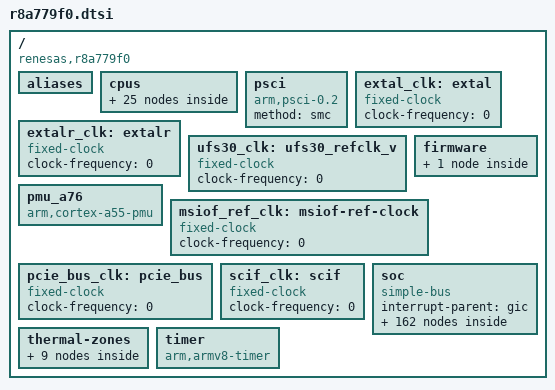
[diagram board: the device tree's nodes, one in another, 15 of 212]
// SPDX-License-Identifier: GPL-2.0
/*
 * Device Tree Source for the R-Car S4 (R8A779F0) SoC
 *
 * Copyright (C) 2021 Renesas Electronics Corp.
 */

#include <dt-bindings/clock/r8a779f0-cpg-mssr.h>
#include <dt-bindings/interrupt-controller/arm-gic.h>
#include <dt-bindings/power/r8a779f0-sysc.h>
#include <dt-bindings/ipmmu/rcar-ipmmu.h>
/ {
	compatible = "renesas,r8a779f0";
	#address-cells = <2>;
	#size-cells = <2>;

	aliases {
		i2c0 = &i2c0;
		i2c1 = &i2c1;
		i2c2 = &i2c2;
		i2c3 = &i2c3;
		i2c4 = &i2c4;
		i2c5 = &i2c5;
	};


	cpus {
		#address-cells = <1>;
		#size-cells = <0>;

		cpu-map {
			cluster0 {
				core0 {
					cpu = <&a55_0>;
				};
				core1 {
					cpu = <&a55_1>;
				};
			};
			cluster1 {
				core0 {
					cpu = <&a55_2>;
				};
				core1 {
					cpu = <&a55_3>;
				};
			};
			cluster2 {
				core0 {
					cpu = <&a55_4>;
				};
				core1 {
					cpu = <&a55_5>;
				};
			};
			cluster3 {
				core0 {
					cpu = <&a55_6>;
				};
				core1 {
					cpu = <&a55_7>;
				};
			};
		};

		a55_0: cpu@0 {
			compatible = "arm,cortex-a55";
			reg = <0>;
			device_type = "cpu";
			power-domains = <&sysc R8A779F0_PD_A1E0D0C0>;
			enable-method = "psci";
			next-level-cache = <&L3_CA55_0>;
		};

		a55_1: cpu@100 {
			compatible = "arm,cortex-a55";
			reg = <0x100>;
			device_type = "cpu";
			power-domains = <&sysc R8A779F0_PD_A1E0D0C1>;
			enable-method = "psci";
			next-level-cache = <&L3_CA55_0>;
		};

		a55_2: cpu@10000 {
			compatible = "arm,cortex-a55";
			reg = <0x10000>;
			device_type = "cpu";
			power-domains = <&sysc R8A779F0_PD_A1E0D1C0>;
			enable-method = "psci";
			next-level-cache = <&L3_CA55_1>;
		};

		a55_3: cpu@10100 {
			compatible = "arm,cortex-a55";
			reg = <0x10100>;
			device_type = "cpu";
			power-domains = <&sysc R8A779F0_PD_A1E0D1C1>;
			enable-method = "psci";
			next-level-cache = <&L3_CA55_1>;
		};

		a55_4: cpu@20000 {
			compatible = "arm,cortex-a55";
			reg = <0x20000>;
			device_type = "cpu";
			power-domains = <&sysc R8A779F0_PD_A1E1D0C0>;
			enable-method = "psci";
			next-level-cache = <&L3_CA55_2>;
		};

		a55_5: cpu@20100 {
			compatible = "arm,cortex-a55";
			reg = <0x20100>;
			device_type = "cpu";
			power-domains = <&sysc R8A779F0_PD_A1E1D0C1>;
			enable-method = "psci";
			next-level-cache = <&L3_CA55_2>;
		};

		a55_6: cpu@30000 {
			compatible = "arm,cortex-a55";
			reg = <0x30000>;
			device_type = "cpu";
			power-domains = <&sysc R8A779F0_PD_A1E1D1C0>;
			enable-method = "psci";
			next-level-cache = <&L3_CA55_3>;
		};

		a55_7: cpu@30100 {
			compatible = "arm,cortex-a55";
			reg = <0x30100>;
			device_type = "cpu";
			power-domains = <&sysc R8A779F0_PD_A1E1D1C1>;
			enable-method = "psci";
			next-level-cache = <&L3_CA55_3>;
		};

		L3_CA55_0: cache-controller-0 {
			compatible = "cache";
			power-domains = <&sysc R8A779F0_PD_A2E0D0>;
			cache-unified;
			cache-level = <3>;
		};

		L3_CA55_1: cache-controller-1 {
			compatible = "cache";
			power-domains = <&sysc R8A779F0_PD_A2E0D1>;
			cache-unified;
			cache-level = <3>;
		};

		L3_CA55_2: cache-controller-2 {
			compatible = "cache";
			power-domains = <&sysc R8A779F0_PD_A2E1D0>;
			cache-unified;
			cache-level = <3>;
		};

		L3_CA55_3: cache-controller-3 {
			compatible = "cache";
			power-domains = <&sysc R8A779F0_PD_A2E1D1>;
			cache-unified;
			cache-level = <3>;
		};
	};

	psci {
		compatible = "arm,psci-0.2";
		method = "smc";
	};

	extal_clk: extal {
		compatible = "fixed-clock";
		#clock-cells = <0>;
		/* This value must be overridden by the board */
		clock-frequency = <0>;
	};

	extalr_clk: extalr {
		compatible = "fixed-clock";
		#clock-cells = <0>;
		/* This value must be overridden by the board */
		clock-frequency = <0>;
	};

	ufs30_clk: ufs30_refclk_v {
		compatible = "fixed-clock";
		#clock-cells = <0>;
		/* This value must be overridden by the board */
		clock-frequency = <0>;
	};

	firmware {
		optee {
			compatible = "linaro,optee-tz";
			method = "smc";
		};
	};

	pmu_a76 {
		compatible = "arm,cortex-a55-pmu";
		interrupts-extended = <&gic GIC_PPI 7 IRQ_TYPE_LEVEL_LOW>;
	};

	/* MSIOF reference clock - to be overridden by boards that provide it */
	msiof_ref_clk: msiof-ref-clock {
		compatible = "fixed-clock";
		#clock-cells = <0>;
		clock-frequency = <0>;
	};

	/* External PCIe clock - can be overridden by the board */
	pcie_bus_clk: pcie_bus {
		compatible = "fixed-clock";
		#clock-cells = <0>;
		clock-frequency = <0>;
	};

	/* External SCIF clock - to be overridden by boards that provide it */
	scif_clk: scif {
		compatible = "fixed-clock";
		#clock-cells = <0>;
		clock-frequency = <0>;
	};

	soc: soc {
		compatible = "simple-bus";
		interrupt-parent = <&gic>;
		#address-cells = <2>;
		#size-cells = <2>;
		ranges;

		rwdt: watchdog@e6020000 {
			compatible = "renesas,r8a779f0-wdt",
				     "renesas,rcar-gen4-wdt";
			reg = <0 0xe6020000 0 0x0c>;
			clocks = <&cpg CPG_MOD 907>;
			power-domains = <&sysc R8A779F0_PD_ALWAYS_ON>;
			resets = <&cpg 907>;
			status = "disabled";
		};

		pfc: pin-controller@e6050000 {
			compatible = "renesas,pfc-r8a779f0";
			reg = <0 0xe6050000 0 0x16c>, <0 0xe6050800 0 0x16c>,
			      <0 0xe6051000 0 0x16c>, <0 0xe6051800 0 0x16c>,
			      <0 0xdfd90000 0 0x16c>, <0 0xdfd90800 0 0x16c>,
			      <0 0xdfd91000 0 0x16c>, <0 0xdfd91800 0 0x16c>;
		};

		gpio0: gpio@e6050180 {
			compatible = "renesas,gpio-r8a779f0";
			reg = <0 0xe6050180 0 0x54>;
			interrupts = <GIC_SPI 822 IRQ_TYPE_LEVEL_HIGH>;
			#gpio-cells = <2>;
			gpio-controller;
			gpio-ranges = <&pfc 0 0 21>;
			#interrupt-cells = <2>;
			interrupt-controller;
			clocks = <&cpg CPG_MOD 915>;
			power-domains = <&sysc R8A779F0_PD_ALWAYS_ON>;
			resets = <&cpg 915>;
		};

		gpio1: gpio@e6050980 {
			compatible = "renesas,gpio-r8a779f0";
			reg = <0 0xe6050980 0 0x54>;
			interrupts = <GIC_SPI 823 IRQ_TYPE_LEVEL_HIGH>;
			#gpio-cells = <2>;
			gpio-controller;
			gpio-ranges = <&pfc 0 32 25>;
			#interrupt-cells = <2>;
			interrupt-controller;
			clocks = <&cpg CPG_MOD 915>;
			power-domains = <&sysc R8A779F0_PD_ALWAYS_ON>;
			resets = <&cpg 915>;
		};

		gpio2: gpio@e6051180 {
			compatible = "renesas,gpio-r8a779f0";
			reg = <0 0xe6051180 0 0x54>;
			interrupts = <GIC_SPI 824 IRQ_TYPE_LEVEL_HIGH>;
			#gpio-cells = <2>;
			gpio-controller;
			gpio-ranges = <&pfc 0 64 17>;
			#interrupt-cells = <2>;
			interrupt-controller;
			clocks = <&cpg CPG_MOD 915>;
			power-domains = <&sysc R8A779F0_PD_ALWAYS_ON>;
			resets = <&cpg 915>;
		};

		gpio3: gpio@e6051980 {
			compatible = "renesas,gpio-r8a779f0";
			reg = <0 0xe6051980 0 0x54>;
			interrupts = <GIC_SPI 825 IRQ_TYPE_LEVEL_HIGH>;
			#gpio-cells = <2>;
			gpio-controller;
			gpio-ranges = <&pfc 0 96 19>;
			#interrupt-cells = <2>;
			interrupt-controller;
			clocks = <&cpg CPG_MOD 915>;
			power-domains = <&sysc R8A779F0_PD_ALWAYS_ON>;
			resets = <&cpg 915>;
		};

		gpio4: gpio@dfd90180 {
			compatible = "renesas,gpio-r8a779f0";
			reg = <0 0xdfd90180 0 0x54>;
			interrupts = <GIC_SPI 826 IRQ_TYPE_LEVEL_HIGH>;
			#gpio-cells = <2>;
			gpio-controller;
			gpio-ranges = <&pfc 0 128 31>;
			#interrupt-cells = <2>;
			interrupt-controller;
			clocks = <&cpg CPG_MOD 915>;
			power-domains = <&sysc R8A779F0_PD_ALWAYS_ON>;
			resets = <&cpg 915>;
		};

		cpg: clock-controller@e6150000 {
			compatible = "renesas,r8a779f0-cpg-mssr";
			reg = <0 0xe6150000 0 0x4000>;
			clocks = <&extal_clk>, <&extalr_clk>;
			clock-names = "extal", "extalr";
			#clock-cells = <2>;
			#power-domain-cells = <0>;
			#reset-cells = <1>;
		};

		rst: reset-controller@e6160000 {
			compatible = "renesas,r8a779f0-rst";
			reg = <0 0xe6160000 0 0x4000>;
		};

		sysc: system-controller@e6180000 {
			compatible = "renesas,r8a779f0-sysc";
			reg = <0 0xe6180000 0 0x4000>;
			#power-domain-cells = <1>;
		};

		i2c0: i2c@e6500000 {
			compatible = "renesas,i2c-r8a779f0",
				     "renesas,rcar-gen4-i2c";
			reg = <0 0xe6500000 0 0x40>;
			interrupts = <GIC_SPI 238 IRQ_TYPE_LEVEL_HIGH>;
			clocks = <&cpg CPG_MOD 518>;
			power-domains = <&sysc R8A779F0_PD_ALWAYS_ON>;
			resets = <&cpg 518>;
			/* dmas and dma-names placeholder */
			i2c-scl-internal-delay-ns = <110>;
			#address-cells = <1>;
			#size-cells = <0>;
			status = "disabled";
		};

		i2c1: i2c@e6508000 {
			compatible = "renesas,i2c-r8a779f0",
				     "renesas,rcar-gen4-i2c";
			reg = <0 0xe6508000 0 0x40>;
			interrupts = <GIC_SPI 239 IRQ_TYPE_LEVEL_HIGH>;
			clocks = <&cpg CPG_MOD 519>;
			power-domains = <&sysc R8A779F0_PD_ALWAYS_ON>;
			resets = <&cpg 519>;
			/* dmas and dma-names placeholder */
			i2c-scl-internal-delay-ns = <110>;
			#address-cells = <1>;
			#size-cells = <0>;
			status = "disabled";
		};

		i2c2: i2c@e6510000 {
			compatible = "renesas,i2c-r8a779f0",
				     "renesas,rcar-gen4-i2c";
			reg = <GIC_SPI 0xe6510000 0 0x40>;
			interrupts = <0 240 IRQ_TYPE_LEVEL_HIGH>;
			clocks = <&cpg CPG_MOD 520>;
			power-domains = <&sysc R8A779F0_PD_ALWAYS_ON>;
			resets = <&cpg 520>;
			/* dmas and dma-names placeholder */
			i2c-scl-internal-delay-ns = <110>;
			#address-cells = <1>;
			#size-cells = <0>;
			status = "disabled";
		};

		i2c3: i2c@e66d0000 {
			compatible = "renesas,i2c-r8a779f0",
				     "renesas,rcar-gen4-i2c";
			reg = <0 0xe66d0000 0 0x40>;
			interrupts = <GIC_SPI 241 IRQ_TYPE_LEVEL_HIGH>;
			clocks = <&cpg CPG_MOD 521>;
			power-domains = <&sysc R8A779F0_PD_ALWAYS_ON>;
			resets = <&cpg 521>;
			/* dmas and dma-names placeholder */
			i2c-scl-internal-delay-ns = <110>;
			#address-cells = <1>;
			#size-cells = <0>;
			status = "disabled";
		};

		i2c4: i2c@e66d8000 {
			compatible = "renesas,i2c-r8a779f0",
				     "renesas,rcar-gen4-i2c";
			reg = <0 0xe66d8000 0 0x40>;
			interrupts = <GIC_SPI 242 IRQ_TYPE_LEVEL_HIGH>;
			clocks = <&cpg CPG_MOD 522>;
			power-domains = <&sysc R8A779F0_PD_ALWAYS_ON>;
			resets = <&cpg 522>;
			/* dmas and dma-names placeholder */
			i2c-scl-internal-delay-ns = <110>;
			#address-cells = <1>;
			#size-cells = <0>;
			status = "disabled";
		};

		i2c5: i2c@e66e0000 {
			compatible = "renesas,i2c-r8a779f0",
				     "renesas,rcar-gen4-i2c";
			reg = <0 0xe66e0000 0 0x40>;
			interrupts = <GIC_SPI 243 IRQ_TYPE_LEVEL_HIGH>;
			clocks = <&cpg CPG_MOD 523>;
			power-domains = <&sysc R8A779F0_PD_ALWAYS_ON>;
			resets = <&cpg 523>;
			/* dmas and dma-names placeholder */
			i2c-scl-internal-delay-ns = <110>;
			#address-cells = <1>;
			#size-cells = <0>;
			status = "disabled";
		};

		tsc: thermal@e6198000 {
			compatible = "renesas,r8a779f0-thermal";
			reg = <0 0xe6198000 0 0x100>,
			      <0 0xe61a0000 0 0x100>,
			      <0 0xe61a8000 0 0x100>,
			      <0 0xe61b0000 0 0x100>;
			clocks = <&cpg CPG_MOD 919>;
			power-domains = <&sysc R8A779F0_PD_ALWAYS_ON>;
			resets = <&cpg 919>;
			#thermal-sensor-cells = <1>;
		};

		hscif0: serial@e6540000 {
			compatible = "renesas,hscif-r8a779f0",
				     "renesas,rcar-gen4-hscif", "renesas,hscif";
			reg = <0 0xe6540000 0 0x60>;
			interrupts = <GIC_SPI 245 IRQ_TYPE_LEVEL_HIGH>;
			clocks = <&cpg CPG_MOD 514>,
				 <&cpg CPG_CORE R8A779F0_CLK_S0D3>,
				 <&scif_clk>;
			clock-names = "fck", "brg_int", "scif_clk";
			/* dmas and dma-names placeholder */
			power-domains = <&sysc R8A779F0_PD_ALWAYS_ON>;
			resets = <&cpg 514>;
			status = "disabled";
		};

		hscif1: serial@e6550000 {
			compatible = "renesas,hscif-r8a779f0",
				     "renesas,rcar-gen4-hscif", "renesas,hscif";
			reg = <0 0xe6550000 0 0x60>;
			interrupts = <GIC_SPI 246 IRQ_TYPE_LEVEL_HIGH>;
			clocks = <&cpg CPG_MOD 515>,
				 <&cpg CPG_CORE R8A779F0_CLK_S0D3>,
				 <&scif_clk>;
			clock-names = "fck", "brg_int", "scif_clk";
			/* dmas and dma-names placeholder */
			power-domains = <&sysc R8A779F0_PD_ALWAYS_ON>;
			resets = <&cpg 515>;
			status = "disabled";
		};

		hscif2: serial@e6560000 {
			compatible = "renesas,hscif-r8a779f0",
				     "renesas,rcar-gen4-hscif", "renesas,hscif";
			reg = <0 0xe6560000 0 0x60>;
			interrupts = <GIC_SPI 247 IRQ_TYPE_LEVEL_HIGH>;
			clocks = <&cpg CPG_MOD 516>,
				 <&cpg CPG_CORE R8A779F0_CLK_S0D3>,
				 <&scif_clk>;
			clock-names = "fck", "brg_int", "scif_clk";
			/* dmas and dma-names placeholder */
			power-domains = <&sysc R8A779F0_PD_ALWAYS_ON>;
			resets = <&cpg 516>;
			status = "disabled";
		};

		hscif3: serial@e66a0000 {
			compatible = "renesas,hscif-r8a779f0",
				     "renesas,rcar-gen4-hscif", "renesas,hscif";
			reg = <0 0xe66a0000 0 0x60>;
			interrupts = <GIC_SPI 248 IRQ_TYPE_LEVEL_HIGH>;
			clocks = <&cpg CPG_MOD 517>,
				 <&cpg CPG_CORE R8A779F0_CLK_S0D3>,
				 <&scif_clk>;
			clock-names = "fck", "brg_int", "scif_clk";
			/* dmas and dma-names placeholder */
			power-domains = <&sysc R8A779F0_PD_ALWAYS_ON>;
			resets = <&cpg 517>;
			status = "disabled";
		};

		rswitch: ethernet@e68c0000 {
			compatible = "renesas,etherswitch-r8a779f0",
				     "renesas,etherswitch";
			reg = <0 0xe68c0000 0 0x00020000>,
			      <0 0xe6444000 0 0x2800>;
			reg-names = "iobase", "serdes";
			interrupts = <GIC_SPI 280 IRQ_TYPE_LEVEL_HIGH>,
				     <GIC_SPI 281 IRQ_TYPE_LEVEL_HIGH>,
				     <GIC_SPI 282 IRQ_TYPE_LEVEL_HIGH>,
				     <GIC_SPI 283 IRQ_TYPE_LEVEL_HIGH>,
				     <GIC_SPI 284 IRQ_TYPE_LEVEL_HIGH>,
				     <GIC_SPI 285 IRQ_TYPE_LEVEL_HIGH>,
				     <GIC_SPI 286 IRQ_TYPE_LEVEL_HIGH>,
				     <GIC_SPI 287 IRQ_TYPE_LEVEL_HIGH>,
				     <GIC_SPI 288 IRQ_TYPE_LEVEL_HIGH>,
				     <GIC_SPI 289 IRQ_TYPE_LEVEL_HIGH>,
				     <GIC_SPI 290 IRQ_TYPE_LEVEL_HIGH>,
				     <GIC_SPI 291 IRQ_TYPE_LEVEL_HIGH>,
				     <GIC_SPI 292 IRQ_TYPE_LEVEL_HIGH>,
				     <GIC_SPI 293 IRQ_TYPE_LEVEL_HIGH>,
				     <GIC_SPI 294 IRQ_TYPE_LEVEL_HIGH>,
				     <GIC_SPI 295 IRQ_TYPE_LEVEL_HIGH>,
				     <GIC_SPI 296 IRQ_TYPE_LEVEL_HIGH>,
				     <GIC_SPI 297 IRQ_TYPE_LEVEL_HIGH>,
				     <GIC_SPI 298 IRQ_TYPE_LEVEL_HIGH>,
				     <GIC_SPI 299 IRQ_TYPE_LEVEL_HIGH>;
			interrupt-names = "gwca0_rxtx0", "gwca0_rxtx1",
					  "gwca0_rxtx2", "gwca0_rxtx3",
					  "gwca0_rxtx4", "gwca0_rxtx5",
					  "gwca0_rxtx6", "gwca0_rxtx7",
					  "gwca1_rxtx0", "gwca1_rxtx1",
					  "gwca1_rxtx2", "gwca1_rxtx3",
					  "gwca1_rxtx4", "gwca1_rxtx5",
					  "gwca1_rxtx6", "gwca1_rxtx7",
					  "gwca0_rxts0", "gwca0_rxts1",
					  "gwca1_rxts0", "gwca1_rxts1";
			#address-cells = <1>;
			#size-cells = <0>;
			clocks = <&cpg CPG_MOD 1505>,
				<&cpg CPG_MOD 1506>;
			clock-names = "rsw2", "eth-phy";
			power-domains = <&sysc R8A779F0_PD_ALWAYS_ON>;
			resets = <&cpg 1505>, <&cpg 1506>;
			status = "disabled";
		};

		scif0: serial@e6e60000 {
			compatible = "renesas,scif-r8a779f0",
				     "renesas,rcar-gen4-scif", "renesas,scif";
			reg = <0 0xe6e60000 0 0x64>;
			interrupts = <GIC_SPI 249 IRQ_TYPE_LEVEL_HIGH>;
			clocks = <&cpg CPG_MOD 702>,
				 <&cpg CPG_CORE R8A779F0_CLK_S0D3_PER>,
				 <&scif_clk>;
			clock-names = "fck", "brg_int", "scif_clk";
			/* dmas and dma-names placeholder */
			power-domains = <&sysc R8A779F0_PD_ALWAYS_ON>;
			resets = <&cpg 702>;
			status = "disabled";
		};

		scif1: serial@e6e68000 {
			compatible = "renesas,scif-r8a779f0",
				     "renesas,rcar-gen4-scif", "renesas,scif";
			reg = <0 0xe6e68000 0 0x64>;
			interrupts = <GIC_SPI 250 IRQ_TYPE_LEVEL_HIGH>;
			clocks = <&cpg CPG_MOD 703>,
				 <&cpg CPG_CORE R8A779F0_CLK_S0D3_PER>,
				 <&scif_clk>;
			clock-names = "fck", "brg_int", "scif_clk";
			/* dmas and dma-names placeholder */
			power-domains = <&sysc R8A779F0_PD_ALWAYS_ON>;
			resets = <&cpg 703>;
			status = "disabled";
		};

		scif3: serial@e6c50000 {
			compatible = "renesas,scif-r8a779f0",
				     "renesas,rcar-gen4-scif", "renesas,scif";
			reg = <0 0xe6c50000 0 0x64>;
			interrupts = <GIC_SPI 252 IRQ_TYPE_LEVEL_HIGH>;
			clocks = <&cpg CPG_MOD 704>,
				 <&cpg CPG_CORE R8A779F0_CLK_S0D3_PER>,
				 <&scif_clk>;
			clock-names = "fck", "brg_int", "scif_clk";
			/* dmas and dma-names placeholder */
			power-domains = <&sysc R8A779F0_PD_ALWAYS_ON>;
			resets = <&cpg 704>;
			status = "disabled";
		};

		scif4: serial@e6c40000 {
			compatible = "renesas,scif-r8a779f0",
				     "renesas,rcar-gen4-scif", "renesas,scif";
			reg = <0 0xe6c40000 0 0x64>;
			interrupts = <GIC_SPI 253 IRQ_TYPE_LEVEL_HIGH>;
			clocks = <&cpg CPG_MOD 705>,
				 <&cpg CPG_CORE R8A779F0_CLK_S0D3_PER>,
				 <&scif_clk>;
			clock-names = "fck", "brg_int", "scif_clk";
			/* dmas and dma-names placeholder */
			power-domains = <&sysc R8A779F0_PD_ALWAYS_ON>;
			resets = <&cpg 705>;
			status = "disabled";
		};

		msiof0: spi@e6e90000 {
			compatible = "renesas,msiof-r8a779f0",
				     "renesas,rcar-gen4-msiof";
			reg = <0 0xe6e90000 0 0x0064>;
			interrupts = <GIC_SPI 230 IRQ_TYPE_LEVEL_HIGH>;
			clocks = <&cpg CPG_MOD 618>, <&msiof_ref_clk>;
			clock-names = "msiof_clk", "msiof_ref_clk";
			/* dmas and dma-names placeholder */
			power-domains = <&sysc R8A779F0_PD_ALWAYS_ON>;
			resets = <&cpg 618>;
			#address-cells = <1>;
			#size-cells = <0>;
			status = "disabled";
		};

		msiof1: spi@e6ea0000 {
			compatible = "renesas,msiof-r8a779f0",
				     "renesas,rcar-gen4-msiof";
			reg = <0 0xe6ea0000 0 0x0064>;
			interrupts = <GIC_SPI 231 IRQ_TYPE_LEVEL_HIGH>;
			clocks = <&cpg CPG_MOD 619>, <&msiof_ref_clk>;
			clock-names = "msiof_clk", "msiof_ref_clk";
			/* dmas and dma-names placeholder */
			power-domains = <&sysc R8A779F0_PD_ALWAYS_ON>;
			resets = <&cpg 619>;
			#address-cells = <1>;
			#size-cells = <0>;
			status = "disabled";
		};

		msiof2: spi@e6c00000 {
			compatible = "renesas,msiof-r8a779f0",
				     "renesas,rcar-gen4-msiof";
			reg = <0 0xe6c00000 0 0x0064>;
			interrupts = <GIC_SPI 232 IRQ_TYPE_LEVEL_HIGH>;
			clocks = <&cpg CPG_MOD 620>, <&msiof_ref_clk>;
			clock-names = "msiof_clk", "msiof_ref_clk";
			/* dmas and dma-names placeholder */
			power-domains = <&sysc R8A779F0_PD_ALWAYS_ON>;
			resets = <&cpg 620>;
			#address-cells = <1>;
			#size-cells = <0>;
			status = "disabled";
		};

		msiof3: spi@e6c10000 {
			compatible = "renesas,msiof-r8a779f0",
				     "renesas,rcar-gen4-msiof";
			reg = <0 0xe6c10000 0 0x0064>;
			interrupts = <GIC_SPI 233 IRQ_TYPE_LEVEL_HIGH>;
			clocks = <&cpg CPG_MOD 621>, <&msiof_ref_clk>;
			clock-names = "msiof_clk", "msiof_ref_clk";
			/* dmas and dma-names placeholder */
			power-domains = <&sysc R8A779F0_PD_ALWAYS_ON>;
			resets = <&cpg 621>;
			#address-cells = <1>;
			#size-cells = <0>;
			status = "disabled";
		};

		dmac1: dma-controller@e7350000 {
			compatible = "renesas,dmac-r8a779f0";
			reg = <0 0xe7350000 0 0x1000>,
			      <0 0xe7300000 0 0x10000>;
			interrupts = <GIC_SPI 101 IRQ_TYPE_LEVEL_HIGH>,
				     <GIC_SPI 102 IRQ_TYPE_LEVEL_HIGH>,
				     <GIC_SPI 103 IRQ_TYPE_LEVEL_HIGH>,
				     <GIC_SPI 104 IRQ_TYPE_LEVEL_HIGH>,
				     <GIC_SPI 105 IRQ_TYPE_LEVEL_HIGH>,
				     <GIC_SPI 106 IRQ_TYPE_LEVEL_HIGH>,
				     <GIC_SPI 107 IRQ_TYPE_LEVEL_HIGH>,
				     <GIC_SPI 108 IRQ_TYPE_LEVEL_HIGH>,
				     <GIC_SPI 109 IRQ_TYPE_LEVEL_HIGH>,
				     <GIC_SPI 110 IRQ_TYPE_LEVEL_HIGH>,
				     <GIC_SPI 111 IRQ_TYPE_LEVEL_HIGH>,
				     <GIC_SPI 112 IRQ_TYPE_LEVEL_HIGH>,
				     <GIC_SPI 113 IRQ_TYPE_LEVEL_HIGH>,
				     <GIC_SPI 114 IRQ_TYPE_LEVEL_HIGH>,
				     <GIC_SPI 115 IRQ_TYPE_LEVEL_HIGH>,
				     <GIC_SPI 116 IRQ_TYPE_LEVEL_HIGH>,
				     <GIC_SPI 117 IRQ_TYPE_LEVEL_HIGH>;
			interrupt-names = "error",
					  "ch0", "ch1", "ch2", "ch3", "ch4",
					  "ch5", "ch6", "ch7", "ch8", "ch9",
					  "ch10", "ch11", "ch12", "ch13",
					  "ch14", "ch15";
			clocks = <&cpg CPG_MOD 709>;
			clock-names = "fck";
			power-domains = <&sysc R8A779F0_PD_ALWAYS_ON>;
			resets = <&cpg 709>;
			#dma-cells = <1>;
			dma-channels = <16>;
			iommus = <&ipmmu_ds0 0>, <&ipmmu_ds0 1>,
			       <&ipmmu_ds0 2>, <&ipmmu_ds0 3>,
			       <&ipmmu_ds0 4>, <&ipmmu_ds0 5>,
			       <&ipmmu_ds0 6>, <&ipmmu_ds0 7>,
			       <&ipmmu_ds0 8>, <&ipmmu_ds0 9>,
			       <&ipmmu_ds0 10>, <&ipmmu_ds0 11>,
			       <&ipmmu_ds0 12>, <&ipmmu_ds0 13>,
			       <&ipmmu_ds0 14>, <&ipmmu_ds0 15>;
		};

		dmac2: dma-controller@e7351000 {
			compatible = "renesas,dmac-r8a779f0";
			reg = <0 0xe7351000 0 0x1000>,
			      <0 0xe7310000 0 0x10000>;
			interrupts = <GIC_SPI 119 IRQ_TYPE_LEVEL_HIGH>,
				     <GIC_SPI 120 IRQ_TYPE_LEVEL_HIGH>,
				     <GIC_SPI 121 IRQ_TYPE_LEVEL_HIGH>,
				     <GIC_SPI 122 IRQ_TYPE_LEVEL_HIGH>,
				     <GIC_SPI 123 IRQ_TYPE_LEVEL_HIGH>,
				     <GIC_SPI 124 IRQ_TYPE_LEVEL_HIGH>,
				     <GIC_SPI 125 IRQ_TYPE_LEVEL_HIGH>,
				     <GIC_SPI 126 IRQ_TYPE_LEVEL_HIGH>,
				     <GIC_SPI 127 IRQ_TYPE_LEVEL_HIGH>,
				     <GIC_SPI 147 IRQ_TYPE_LEVEL_HIGH>,
				     <GIC_SPI 148 IRQ_TYPE_LEVEL_HIGH>,
				     <GIC_SPI 149 IRQ_TYPE_LEVEL_HIGH>,
				     <GIC_SPI 150 IRQ_TYPE_LEVEL_HIGH>,
				     <GIC_SPI 151 IRQ_TYPE_LEVEL_HIGH>,
				     <GIC_SPI 152 IRQ_TYPE_LEVEL_HIGH>,
				     <GIC_SPI 153 IRQ_TYPE_LEVEL_HIGH>,
				     <GIC_SPI 154 IRQ_TYPE_LEVEL_HIGH>;
			interrupt-names = "error",
					  "ch0", "ch1", "ch2", "ch3", "ch4",
					  "ch5", "ch6", "ch7", "ch8", "ch9",
					  "ch10", "ch11", "ch12", "ch13",
					  "ch14", "ch15";
			clocks = <&cpg CPG_MOD 710>;
			clock-names = "fck";
			power-domains = <&sysc R8A779F0_PD_ALWAYS_ON>;
			resets = <&cpg 710>;
			#dma-cells = <1>;
			dma-channels = <16>;
			iommus = <&ipmmu_ds0 16>, <&ipmmu_ds0 17>,
			       <&ipmmu_ds0 18>, <&ipmmu_ds0 19>,
			       <&ipmmu_ds0 20>, <&ipmmu_ds0 21>,
			       <&ipmmu_ds0 22>, <&ipmmu_ds0 23>,
			       <&ipmmu_ds0 24>, <&ipmmu_ds0 25>,
			       <&ipmmu_ds0 26>, <&ipmmu_ds0 27>,
			       <&ipmmu_ds0 28>, <&ipmmu_ds0 29>,
			       <&ipmmu_ds0 30>, <&ipmmu_ds0 31>;
		};

		mmc0: mmc@ee140000 {
			compatible = "renesas,sdhi-r8a779f0",
				     "renesas,rcar-gen4-sdhi";
			reg = <0 0xee140000 0 0x2000>;
			interrupts = <GIC_SPI 236 IRQ_TYPE_LEVEL_HIGH>;
			clocks = <&cpg CPG_MOD 706>;
			power-domains = <&sysc R8A779F0_PD_ALWAYS_ON>;
			resets = <&cpg 706>;
			max-frequency = <200000000>;
			status = "disabled";
		};

		rpc: spi@ee200000 {
			compatible = "renesas,r8a779f0-rpc-if",
				     "renesas,rcar-gen4-rpc-if";
			reg = <0 0xee200000 0 0x200>,
			      <0 0x08000000 0 0x04000000>,
			      <0 0xee208000 0 0x100>;
			reg-names = "regs", "dirmap", "wbuf";
			interrupts = <GIC_SPI 135 IRQ_TYPE_LEVEL_HIGH>;
			clocks = <&cpg CPG_MOD 629>;
			clock-names = "rpc";
			power-domains = <&sysc R8A779F0_PD_ALWAYS_ON>;
			resets = <&cpg 629>;
			#address-cells = <1>;
			#size-cells = <0>;
			status = "disabled";
		};

		gic: interrupt-controller@f1000000 {
			compatible = "arm,gic-v3";
			#interrupt-cells = <3>;
			#address-cells = <0>;
			interrupt-controller;
			reg = <0x0 0xf1000000 0 0x20000>,
			      <0x0 0xf1060000 0 0x110000>;
			interrupts = <GIC_PPI 9
				      (GIC_CPU_MASK_SIMPLE(8) | IRQ_TYPE_LEVEL_HIGH)>;
		};

		prr: chipid@fff00044 {
			compatible = "renesas,prr";
			reg = <0 0xfff00044 0 4>;
		};

		rt_dmac0: dma-controller@ffd60000 {
			compatible = "renesas,dmac-r8a779f0";
			reg = <0 0xffd60000 0 0x1000>,
			      <0 0xffc10000 0 0x10000>;
			interrupts = <GIC_SPI 29 IRQ_TYPE_LEVEL_HIGH>,
				     <GIC_SPI 30 IRQ_TYPE_LEVEL_HIGH>,
				     <GIC_SPI 31 IRQ_TYPE_LEVEL_HIGH>,
				     <GIC_SPI 32 IRQ_TYPE_LEVEL_HIGH>,
				     <GIC_SPI 33 IRQ_TYPE_LEVEL_HIGH>,
				     <GIC_SPI 34 IRQ_TYPE_LEVEL_HIGH>,
				     <GIC_SPI 35 IRQ_TYPE_LEVEL_HIGH>,
				     <GIC_SPI 36 IRQ_TYPE_LEVEL_HIGH>,
				     <GIC_SPI 37 IRQ_TYPE_LEVEL_HIGH>,
				     <GIC_SPI 38 IRQ_TYPE_LEVEL_HIGH>,
				     <GIC_SPI 39 IRQ_TYPE_LEVEL_HIGH>,
				     <GIC_SPI 40 IRQ_TYPE_LEVEL_HIGH>,
				     <GIC_SPI 41 IRQ_TYPE_LEVEL_HIGH>,
				     <GIC_SPI 42 IRQ_TYPE_LEVEL_HIGH>,
				     <GIC_SPI 43 IRQ_TYPE_LEVEL_HIGH>,
				     <GIC_SPI 44 IRQ_TYPE_LEVEL_HIGH>,
				     <GIC_SPI 45 IRQ_TYPE_LEVEL_HIGH>;
			interrupt-names = "error",
					  "ch0", "ch1", "ch2", "ch3", "ch4",
					  "ch5", "ch6", "ch7", "ch8", "ch9",
					  "ch10", "ch11", "ch12", "ch13",
					  "ch14", "ch15";
			clocks = <&cpg CPG_MOD 630>;
			clock-names = "fck";
			power-domains = <&sysc R8A779F0_PD_ALWAYS_ON>;
			resets = <&cpg 630>;
			#dma-cells = <1>;
			dma-channels = <16>;
		};

		rt_dmac1: dma-controller@ffd61000 {
			compatible = "renesas,dmac-r8a779f0";
			reg = <0 0xffd61000 0 0x1000>,
			      <0 0xffc20000 0 0x10000>;
			interrupts = <GIC_SPI 47 IRQ_TYPE_LEVEL_HIGH>,
				     <GIC_SPI 48 IRQ_TYPE_LEVEL_HIGH>,
				     <GIC_SPI 49 IRQ_TYPE_LEVEL_HIGH>,
				     <GIC_SPI 50 IRQ_TYPE_LEVEL_HIGH>,
				     <GIC_SPI 51 IRQ_TYPE_LEVEL_HIGH>,
				     <GIC_SPI 52 IRQ_TYPE_LEVEL_HIGH>,
				     <GIC_SPI 53 IRQ_TYPE_LEVEL_HIGH>,
				     <GIC_SPI 54 IRQ_TYPE_LEVEL_HIGH>,
				     <GIC_SPI 55 IRQ_TYPE_LEVEL_HIGH>,
				     <GIC_SPI 56 IRQ_TYPE_LEVEL_HIGH>,
				     <GIC_SPI 57 IRQ_TYPE_LEVEL_HIGH>,
				     <GIC_SPI 58 IRQ_TYPE_LEVEL_HIGH>,
				     <GIC_SPI 59 IRQ_TYPE_LEVEL_HIGH>,
				     <GIC_SPI 60 IRQ_TYPE_LEVEL_HIGH>,
				     <GIC_SPI 61 IRQ_TYPE_LEVEL_HIGH>,
				     <GIC_SPI 62 IRQ_TYPE_LEVEL_HIGH>,
				     <GIC_SPI 63 IRQ_TYPE_LEVEL_HIGH>;
			interrupt-names = "error",
					  "ch0", "ch1", "ch2", "ch3", "ch4",
					  "ch5", "ch6", "ch7", "ch8", "ch9",
					  "ch10", "ch11", "ch12", "ch13",
					  "ch14", "ch15";
			clocks = <&cpg CPG_MOD 631>;
			clock-names = "fck";
			power-domains = <&sysc R8A779F0_PD_ALWAYS_ON>;
			resets = <&cpg 631>;
			#dma-cells = <1>;
			dma-channels = <16>;
		};

		rt_dmac2: dma-controller@ffd62000 {
			compatible = "renesas,dmac-r8a779f0";
			reg = <0 0xffd62000 0 0x1000>,
			      <0 0xffd70000 0 0x10000>;
			interrupts = <GIC_SPI 65 IRQ_TYPE_LEVEL_HIGH>,
				     <GIC_SPI 66 IRQ_TYPE_LEVEL_HIGH>,
				     <GIC_SPI 67 IRQ_TYPE_LEVEL_HIGH>,
				     <GIC_SPI 68 IRQ_TYPE_LEVEL_HIGH>,
				     <GIC_SPI 69 IRQ_TYPE_LEVEL_HIGH>,
				     <GIC_SPI 70 IRQ_TYPE_LEVEL_HIGH>,
				     <GIC_SPI 71 IRQ_TYPE_LEVEL_HIGH>,
				     <GIC_SPI 72 IRQ_TYPE_LEVEL_HIGH>,
				     <GIC_SPI 73 IRQ_TYPE_LEVEL_HIGH>,
				     <GIC_SPI 74 IRQ_TYPE_LEVEL_HIGH>,
				     <GIC_SPI 75 IRQ_TYPE_LEVEL_HIGH>,
				     <GIC_SPI 76 IRQ_TYPE_LEVEL_HIGH>,
				     <GIC_SPI 77 IRQ_TYPE_LEVEL_HIGH>,
				     <GIC_SPI 78 IRQ_TYPE_LEVEL_HIGH>,
				     <GIC_SPI 79 IRQ_TYPE_LEVEL_HIGH>,
				     <GIC_SPI 80 IRQ_TYPE_LEVEL_HIGH>,
				     <GIC_SPI 81 IRQ_TYPE_LEVEL_HIGH>;
			interrupt-names = "error",
					  "ch0", "ch1", "ch2", "ch3", "ch4",
					  "ch5", "ch6", "ch7", "ch8", "ch9",
					  "ch10", "ch11", "ch12", "ch13",
					  "ch14", "ch15";
			clocks = <&cpg CPG_MOD 700>;
			clock-names = "fck";
			power-domains = <&sysc R8A779F0_PD_ALWAYS_ON>;
			resets = <&cpg 700>;
			#dma-cells = <1>;
			dma-channels = <16>;
		};

		rt_dmac3: dma-controller@ffd63000 {
			compatible = "renesas,dmac-r8a779f0";
			reg = <0 0xffd63000 0 0x1000>,
			      <0 0xffd80000 0 0x10000>;
			interrupts = <GIC_SPI 83 IRQ_TYPE_LEVEL_HIGH>,
				     <GIC_SPI 84 IRQ_TYPE_LEVEL_HIGH>,
				     <GIC_SPI 85 IRQ_TYPE_LEVEL_HIGH>,
				     <GIC_SPI 86 IRQ_TYPE_LEVEL_HIGH>,
				     <GIC_SPI 87 IRQ_TYPE_LEVEL_HIGH>,
				     <GIC_SPI 88 IRQ_TYPE_LEVEL_HIGH>,
				     <GIC_SPI 89 IRQ_TYPE_LEVEL_HIGH>,
				     <GIC_SPI 90 IRQ_TYPE_LEVEL_HIGH>,
				     <GIC_SPI 91 IRQ_TYPE_LEVEL_HIGH>,
				     <GIC_SPI 92 IRQ_TYPE_LEVEL_HIGH>,
				     <GIC_SPI 93 IRQ_TYPE_LEVEL_HIGH>,
				     <GIC_SPI 94 IRQ_TYPE_LEVEL_HIGH>,
				     <GIC_SPI 95 IRQ_TYPE_LEVEL_HIGH>,
				     <GIC_SPI 96 IRQ_TYPE_LEVEL_HIGH>,
				     <GIC_SPI 97 IRQ_TYPE_LEVEL_HIGH>,
				     <GIC_SPI 98 IRQ_TYPE_LEVEL_HIGH>,
				     <GIC_SPI 99 IRQ_TYPE_LEVEL_HIGH>;
			interrupt-names = "error",
					  "ch0", "ch1", "ch2", "ch3", "ch4",
					  "ch5", "ch6", "ch7", "ch8", "ch9",
					  "ch10", "ch11", "ch12", "ch13",
					  "ch14", "ch15";
			clocks = <&cpg CPG_MOD 701>;
			clock-names = "fck";
			power-domains = <&sysc R8A779F0_PD_ALWAYS_ON>;
			resets = <&cpg 701>;
			#dma-cells = <1>;
			dma-channels = <16>;
		};

		ipmmu_mm: iommu@eefc0000 {
			compatible = "renesas,ipmmu-r8a779f0";
			reg = <0 0xeefc0000 0 0x20000>;
			interrupts = <GIC_SPI 21 IRQ_TYPE_LEVEL_HIGH>,
				     <GIC_SPI 22 IRQ_TYPE_LEVEL_HIGH>;
			power-domains = <&sysc R8A779F0_PD_ALWAYS_ON>;
			#iommu-cells = <1>;
		};

		ipmmu_rt0: iommu@ee480000 {
			compatible = "renesas,ipmmu-r8a779f0";
			reg = <0 0xee480000 0 0x20000>;
			renesas,ipmmu-main = <&ipmmu_mm 10>;
			power-domains = <&sysc R8A779F0_PD_ALWAYS_ON>;
			#iommu-cells = <1>;
			status = "disabled";
		};

		ipmmu_rt1: iommu@ee4c0000 {
                        compatible = "renesas,ipmmu-r8a779f0";
                        reg = <0 0xee4c0000 0 0x20000>;
                        renesas,ipmmu-main = <&ipmmu_mm 10>;
                        power-domains = <&sysc R8A779F0_PD_ALWAYS_ON>;
                        #iommu-cells = <1>;
                        status = "disabled";
                };

		ipmmu_ds0: iommu@eed00000 {
			compatible = "renesas,ipmmu-r8a779f0";
			reg = <0 0xeed00000 0 0x20000>;
			renesas,ipmmu-main = <&ipmmu_mm 0>;
			power-domains = <&sysc R8A779F0_PD_ALWAYS_ON>;
			#iommu-cells = <1>;
		};

		ipmmu_hc: iommu@eed40000 {
			compatible = "renesas,ipmmu-r8a779f0";
			reg = <0 0xeed40000 0 0x20000>;
			renesas,ipmmu-main = <&ipmmu_mm 2>;
			power-domains = <&sysc R8A779F0_PD_ALWAYS_ON>;
			#iommu-cells = <1>;
			status = "disabled";
		};

		pciec0: pcie@e65d0000 {
			compatible = "renesas,r8a779f0-pcie";
			reg = <0 0xe65d0000 0 0x3000>,
			      <0 0xe65d3000 0 0x2000>,
			      <0 0xe65d5000 0 0x1200>,
			      <0 0xe65d6200 0 0x0e00>,
			      <0 0xe65d7000 0 0x1000>,
			      <0 0xfe000000 0 0x10000>;
			reg-names = "dbi",
				    "atu",
				    "dma",
				    "app",
				    "phy",
				    "config";
			#address-cells = <3>;
			#size-cells = <2>;
			bus-range = <0x00 0xff>;
			device_type = "pci";
				 /* downstream IO */
			ranges =  <0x81000000 0 0x00000000 0 0xfe000000 0 0x00010000
				 /* non-prefetchable memory */
				  0x82000000 0 0x30000000 0 0x30000000 0 0x10000000>;
				     /* Map all possible DDR as inbound ranges */
			dma-ranges = <0x42000000 0 0x40000000 0 0x40000000 0 0x80000000>;
			interrupts = <GIC_SPI 416 IRQ_TYPE_LEVEL_HIGH>,
				     <GIC_SPI 417 IRQ_TYPE_LEVEL_HIGH>,
				     <GIC_SPI 418 IRQ_TYPE_LEVEL_HIGH>,
				     <GIC_SPI 419 IRQ_TYPE_LEVEL_HIGH>,
				     <GIC_SPI 420 IRQ_TYPE_LEVEL_HIGH>,
				     <GIC_SPI 421 IRQ_TYPE_LEVEL_HIGH>,
				     <GIC_SPI 422 IRQ_TYPE_LEVEL_HIGH>;
			interrupt-names = "msi", "dma", "err", "fatal",
					  "nonfatal", "lp", "vndmsg";
			#interrupt-cells = <1>;
			interrupt-map-mask = <0 0 0 7>;
			interrupt-map = <0 0 0 1 &gic GIC_SPI 416 IRQ_TYPE_LEVEL_HIGH
					 0 0 0 2 &gic GIC_SPI 416 IRQ_TYPE_LEVEL_HIGH
					 0 0 0 3 &gic GIC_SPI 416 IRQ_TYPE_LEVEL_HIGH
					 0 0 0 4 &gic GIC_SPI 416 IRQ_TYPE_LEVEL_HIGH>;
			clocks = <&cpg CPG_MOD 624>,
				 <&cpg CPG_MOD 625>,
				 <&pcie_bus_clk>;
			clock-names = "pcie0",
				      "pcie1",
				      "pcie_bus";
			power-domains = <&sysc R8A779F0_PD_ALWAYS_ON>;
			resets = <&cpg 624>;
			num-lanes = <2>;
			snps,enable-cdm-check = "true";
			max-link-speed = <2>;
			status = "disabled";
		};

		pciec0_ep: pciec0_ep@e65d0000 {
			compatible = "renesas,r8a779f0-pcie-ep";
			reg = <0 0xe65d0000 0 0x1000>, <0 0xe65d1000 0 0x1000>,
			      <0 0xe65d2000 0 0x1000>, <0 0xe65d3000 0 0x2000>,
			      <0 0xe65d5000 0 0x1200>, <0 0xe65d6200 0 0x0e00>,
			      <0 0xe65d7000 0 0x1000>, <0 0xfe000000 0 0x400000>;
			reg-names = "dbi", "dbi2",
				    "shadow", "atu",
				    "dma", "app",
				    "phy", "addr_space";
			interrupts = <GIC_SPI 416 IRQ_TYPE_LEVEL_HIGH>,
				     <GIC_SPI 417 IRQ_TYPE_LEVEL_HIGH>,
				     <GIC_SPI 418 IRQ_TYPE_LEVEL_HIGH>,
				     <GIC_SPI 419 IRQ_TYPE_LEVEL_HIGH>,
				     <GIC_SPI 420 IRQ_TYPE_LEVEL_HIGH>,
				     <GIC_SPI 421 IRQ_TYPE_LEVEL_HIGH>,
				     <GIC_SPI 422 IRQ_TYPE_LEVEL_HIGH>;
			interrupt-names = "msi", "dma", "err", "fatal",
					  "nonfatal", "lp", "vndmsg";
			clocks = <&cpg CPG_MOD 624>,
				 <&cpg CPG_MOD 625>,
				 <&pcie_bus_clk>;
			clock-names = "pcie0",
				      "pcie1",
				      "pcie_bus";
			power-domains = <&sysc R8A779F0_PD_ALWAYS_ON>;
			resets = <&cpg 624>;
			num-lanes = <2>;
			max-link-speed = <2>;
			num-ib-windows = <16>;
			num-ob-windows = <16>;
			status = "disabled";
		};

		pciec1: pcie@e65d8000 {
			compatible = "renesas,r8a779f0-pcie";
			reg = <0 0xe65d8000 0 0x3000>,
			      <0 0xe65db000 0 0x2000>,
			      <0 0xe65dd000 0 0x1200>,
			      <0 0xe65de200 0 0x0e00>,
			      <0 0xe65df000 0 0x1000>,
			      <0 0xee900000 0 0x10000>;
			reg-names = "dbi",
				    "atu",
				    "dma",
				    "app",
				    "phy",
				    "config";
			#address-cells = <3>;
			#size-cells = <2>;
			bus-range = <0x00 0xff>;
			device_type = "pci";
				 /* downstream IO */
			ranges = <0x81000000 0 0x00000000 0 0xee900000 0 0x00010000
				 /* non-prefetchable memory */
				 0x82000000 0 0xc0000000 0 0xc0000000 0 0x10000000>;
				     /* Map all possible DDR as inbound ranges */
			dma-ranges = <0x42000000 0 0x40000000 0 0x40000000 0 0x80000000>;
			interrupts = <GIC_SPI 423 IRQ_TYPE_LEVEL_HIGH>,
				     <GIC_SPI 424 IRQ_TYPE_LEVEL_HIGH>,
				     <GIC_SPI 425 IRQ_TYPE_LEVEL_HIGH>,
				     <GIC_SPI 426 IRQ_TYPE_LEVEL_HIGH>,
				     <GIC_SPI 427 IRQ_TYPE_LEVEL_HIGH>,
				     <GIC_SPI 428 IRQ_TYPE_LEVEL_HIGH>,
				     <GIC_SPI 429 IRQ_TYPE_LEVEL_HIGH>;
			interrupt-names = "msi", "dma", "err", "fatal",
					  "nonfatal", "lp", "vndmsg";
			#interrupt-cells = <1>;
			interrupt-map-mask = <0 0 0 7>;
			interrupt-map = <0 0 0 1 &gic GIC_SPI 423 IRQ_TYPE_LEVEL_HIGH
					 0 0 0 2 &gic GIC_SPI 423 IRQ_TYPE_LEVEL_HIGH
					 0 0 0 3 &gic GIC_SPI 423 IRQ_TYPE_LEVEL_HIGH
					 0 0 0 4 &gic GIC_SPI 423 IRQ_TYPE_LEVEL_HIGH>;
			clocks = <&cpg CPG_MOD 624>,
				 <&cpg CPG_MOD 625>,
				 <&pcie_bus_clk>;
			clock-names = "pcie0",
				      "pcie1",
				      "pcie_bus";
			power-domains = <&sysc R8A779F0_PD_ALWAYS_ON>;
			resets = <&cpg 625>;
			num-lanes = <2>;
			snps,enable-cdm-check = "true";
			max-link-speed = <2>;
			status = "disabled";
		};

		tau_pwm0: tau@dfbf4000 {
			compatible = "renesas,tau-pwm";
			reg = <0 0xdfbf4000 0 0x1000>,
			      <0 0xdf980000 0 0x10000>,
			      <0 0xe6160000 0 0x8>;
			reg-names = "taud", "clkc", "modemr";
			power-domains = <&sysc R8A779F0_PD_ALWAYS_ON>;
			renesas,channel = <0>;
			status = "disabled";
		};

		tau_pwm1: tau@dfbf5000 {
			compatible = "renesas,tau-pwm";
			reg = <0 0xdfbf5000 0 0x1000>,
			      <0 0xdf980000 0 0x10000>,
			      <0 0xe6160000 0 0x8>;
			reg-names = "taud", "clkc", "modemr";
			power-domains = <&sysc R8A779F0_PD_ALWAYS_ON>;
			renesas,channel = <1>;
			status = "disabled";
		};

		iccom00: mfis@e6260000 {
			compatible = "generic-uio";
			reg = <0 0xe6260000 0 0x10000>;
			interrupts = <GIC_SPI 320 IRQ_TYPE_LEVEL_HIGH>;
			power-domains = <&sysc R8A779F0_PD_ALWAYS_ON>;
			linux,uio-name = "iccom_00";
		};

		iccom01 {
			compatible = "generic-uio";
			reg = <0 0xe6260000 0 0x10000>;
			interrupts = <GIC_SPI 322 IRQ_TYPE_LEVEL_HIGH>;
			power-domains = <&sysc R8A779F0_PD_ALWAYS_ON>;
			linux,uio-name = "irq_iccom_00_01";
		};

		iccom02 {
			compatible = "generic-uio";
			reg = <0 0xe6260000 0 0x10000>;
			interrupts = <GIC_SPI 324 IRQ_TYPE_LEVEL_HIGH>;
			power-domains = <&sysc R8A779F0_PD_ALWAYS_ON>;
			linux,uio-name = "irq_iccom_00_02";
		};

		iccom03 {
			compatible = "generic-uio";
			reg = <0 0xe6260000 0 0x10000>;
			interrupts = <GIC_SPI 326 IRQ_TYPE_LEVEL_HIGH>;
			power-domains = <&sysc R8A779F0_PD_ALWAYS_ON>;
			linux,uio-name = "irq_iccom_00_03";
		};

		iccom04 {
			compatible = "generic-uio";
			reg = <0 0xe6260000 0 0x10000>;
			interrupts = <GIC_SPI 328 IRQ_TYPE_LEVEL_HIGH>;
			power-domains = <&sysc R8A779F0_PD_ALWAYS_ON>;
			linux,uio-name = "irq_iccom_00_04";
		};

		iccom05 {
			compatible = "generic-uio";
			reg = <0 0xe6260000 0 0x10000>;
			interrupts = <GIC_SPI 330 IRQ_TYPE_LEVEL_HIGH>;
			power-domains = <&sysc R8A779F0_PD_ALWAYS_ON>;
			linux,uio-name = "irq_iccom_00_05";
		};

		iccom06 {
			compatible = "generic-uio";
			reg = <0 0xe6260000 0 0x10000>;
			interrupts = <GIC_SPI 332 IRQ_TYPE_LEVEL_HIGH>;
			power-domains = <&sysc R8A779F0_PD_ALWAYS_ON>;
			linux,uio-name = "irq_iccom_00_06";
		};

		iccom07 {
			compatible = "generic-uio";
			reg = <0 0xe6260000 0 0x10000>;
			interrupts = <GIC_SPI 334 IRQ_TYPE_LEVEL_HIGH>;
			power-domains = <&sysc R8A779F0_PD_ALWAYS_ON>;
			linux,uio-name = "irq_iccom_00_07";
		};

		iccom08 {
			compatible = "generic-uio";
			reg = <0 0xe6260000 0 0x10000>;
			interrupts = <GIC_SPI 336 IRQ_TYPE_LEVEL_HIGH>;
			power-domains = <&sysc R8A779F0_PD_ALWAYS_ON>;
			linux,uio-name = "irq_iccom_00_08";
		};

		iccom09 {
			compatible = "generic-uio";
			reg = <0 0xe6260000 0 0x10000>;
			interrupts = <GIC_SPI 338 IRQ_TYPE_LEVEL_HIGH>;
			power-domains = <&sysc R8A779F0_PD_ALWAYS_ON>;
			linux,uio-name = "irq_iccom_00_09";
		};

		iccom010 {
			compatible = "generic-uio";
			reg = <0 0xe6260000 0 0x10000>;
			interrupts = <GIC_SPI 340 IRQ_TYPE_LEVEL_HIGH>;
			power-domains = <&sysc R8A779F0_PD_ALWAYS_ON>;
			linux,uio-name = "irq_iccom_00_10";
		};


		iccom011 {
			compatible = "generic-uio";
			reg = <0 0xe6260000 0 0x10000>;
			interrupts = <GIC_SPI 342 IRQ_TYPE_LEVEL_HIGH>;
			power-domains = <&sysc R8A779F0_PD_ALWAYS_ON>;
			linux,uio-name = "irq_iccom_00_11";
		};

		iccom012 {
			compatible = "generic-uio";
			reg = <0 0xe6260000 0 0x10000>;
			interrupts = <GIC_SPI 344 IRQ_TYPE_LEVEL_HIGH>;
			power-domains = <&sysc R8A779F0_PD_ALWAYS_ON>;
			linux,uio-name = "irq_iccom_00_12";
		};

		iccom013 {
			compatible = "generic-uio";
			reg = <0 0xe6260000 0 0x10000>;
			interrupts = <GIC_SPI 346 IRQ_TYPE_LEVEL_HIGH>;
			power-domains = <&sysc R8A779F0_PD_ALWAYS_ON>;
			linux,uio-name = "irq_iccom_00_13";
		};

		iccom014 {
			compatible = "generic-uio";
			reg = <0 0xe6260000 0 0x10000>;
			interrupts = <GIC_SPI 348 IRQ_TYPE_LEVEL_HIGH>;
			power-domains = <&sysc R8A779F0_PD_ALWAYS_ON>;
			linux,uio-name = "irq_iccom_00_14";
		};

		iccom015 {
			compatible = "generic-uio";
			reg = <0 0xe6260000 0 0x10000>;
			interrupts = <GIC_SPI 350 IRQ_TYPE_LEVEL_HIGH>;
			power-domains = <&sysc R8A779F0_PD_ALWAYS_ON>;
			linux,uio-name = "irq_iccom_00_15";
		};

		iccom016 {
			compatible = "generic-uio";
			reg = <0 0xe6260000 0 0x10000>;
			interrupts = <GIC_SPI 354 IRQ_TYPE_LEVEL_HIGH>;
			power-domains = <&sysc R8A779F0_PD_ALWAYS_ON>;
			linux,uio-name = "irq_iccom_00_16";
		};

		iccom017 {
			compatible = "generic-uio";
			reg = <0 0xe6260000 0 0x10000>;
			interrupts = <GIC_SPI 356 IRQ_TYPE_LEVEL_HIGH>;
			power-domains = <&sysc R8A779F0_PD_ALWAYS_ON>;
			linux,uio-name = "irq_iccom_00_17";
		};

		iccom018 {
			compatible = "generic-uio";
			reg = <0 0xe6260000 0 0x10000>;
			interrupts = <GIC_SPI 358 IRQ_TYPE_LEVEL_HIGH>;
			power-domains = <&sysc R8A779F0_PD_ALWAYS_ON>;
			linux,uio-name = "irq_iccom_00_18";
		};

		iccom019 {
			compatible = "generic-uio";
			reg = <0 0xe6260000 0 0x10000>;
			interrupts = <GIC_SPI 360 IRQ_TYPE_LEVEL_HIGH>;
			power-domains = <&sysc R8A779F0_PD_ALWAYS_ON>;
			linux,uio-name = "irq_iccom_00_19";
		};

		iccom020 {
			compatible = "generic-uio";
			reg = <0 0xe6260000 0 0x10000>;
			interrupts = <GIC_SPI 362 IRQ_TYPE_LEVEL_HIGH>;
			power-domains = <&sysc R8A779F0_PD_ALWAYS_ON>;
			linux,uio-name = "irq_iccom_00_20";
		};

		iccom021 {
			compatible = "generic-uio";
			reg = <0 0xe6260000 0 0x10000>;
			interrupts = <GIC_SPI 364 IRQ_TYPE_LEVEL_HIGH>;
			power-domains = <&sysc R8A779F0_PD_ALWAYS_ON>;
			linux,uio-name = "irq_iccom_00_21";
		};

		iccom022 {
			compatible = "generic-uio";
			reg = <0 0xe6260000 0 0x10000>;
			interrupts = <GIC_SPI 366 IRQ_TYPE_LEVEL_HIGH>;
			power-domains = <&sysc R8A779F0_PD_ALWAYS_ON>;
			linux,uio-name = "irq_iccom_00_22";
		};

		iccom023 {
			compatible = "generic-uio";
			reg = <0 0xe6260000 0 0x10000>;
			interrupts = <GIC_SPI 368 IRQ_TYPE_LEVEL_HIGH>;
			power-domains = <&sysc R8A779F0_PD_ALWAYS_ON>;
			linux,uio-name = "irq_iccom_00_23";
		};

		caiplite0 {
			compatible = "generic-uio";
			reg = <0 0xe7800000 0 0x1000>;
			interrupts = <GIC_SPI 933 IRQ_TYPE_LEVEL_HIGH>;
			clocks = <&cpg CPG_MOD 721>;
			power-domains = <&sysc R8A779F0_PD_ALWAYS_ON>;
			resets = <&cpg 721>;
			linux,uio-name = "caiplite_00";
		};

		caiplite1 {
			compatible = "generic-uio";
			reg = <0 0xe7801000 0 0x1000>;
			interrupts = <GIC_SPI 935 IRQ_TYPE_LEVEL_HIGH>;
			clocks = <&cpg CPG_MOD 722>;
			power-domains = <&sysc R8A779F0_PD_ALWAYS_ON>;
			resets = <&cpg 722>;
			linux,uio-name = "caiplite_01";
		};

		caiplite2 {
			compatible = "generic-uio";
			reg = <0 0xe7802000 0 0x1000>;
			interrupts = <GIC_SPI 937 IRQ_TYPE_LEVEL_HIGH>;
			clocks = <&cpg CPG_MOD 723>;
			power-domains = <&sysc R8A779F0_PD_ALWAYS_ON>;
			resets = <&cpg 723>;
			linux,uio-name = "caiplite_02";
		};

		caiplite3 {
			compatible = "generic-uio";
			reg = <0 0xe7803000 0 0x1000>;
			interrupts = <GIC_SPI 939 IRQ_TYPE_LEVEL_HIGH>;
			clocks = <&cpg CPG_MOD 724>;
			power-domains = <&sysc R8A779F0_PD_ALWAYS_ON>;
			resets = <&cpg 724>;
			linux,uio-name = "caiplite_03";
		};

		caiplite4 {
			compatible = "generic-uio";
			reg = <0 0xe7804000 0 0x1000>;
			interrupts = <GIC_SPI 941 IRQ_TYPE_LEVEL_HIGH>;
			clocks = <&cpg CPG_MOD 725>;
			power-domains = <&sysc R8A779F0_PD_ALWAYS_ON>;
			resets = <&cpg 725>;
			linux,uio-name = "caiplite_04";
		};

		caiplite5 {
			compatible = "generic-uio";
			reg = <0 0xe7805000 0 0x1000>;
			interrupts = <GIC_SPI 943 IRQ_TYPE_LEVEL_HIGH>;
			clocks = <&cpg CPG_MOD 726>;
			power-domains = <&sysc R8A779F0_PD_ALWAYS_ON>;
			resets = <&cpg 726>;
			linux,uio-name = "caiplite_05";
		};

		caiplite6 {
			compatible = "generic-uio";
			reg = <0 0xe7806000 0 0x1000>;
			interrupts = <GIC_SPI 945 IRQ_TYPE_LEVEL_HIGH>;
			clocks = <&cpg CPG_MOD 727>;
			power-domains = <&sysc R8A779F0_PD_ALWAYS_ON>;
			resets = <&cpg 727>;
			linux,uio-name = "caiplite_06";
		};

		caiplite7 {
			compatible = "generic-uio";
			reg = <0 0xe7807000 0 0x1000>;
			interrupts = <GIC_SPI 947 IRQ_TYPE_LEVEL_HIGH>;
			clocks = <&cpg CPG_MOD 728>;
			power-domains = <&sysc R8A779F0_PD_ALWAYS_ON>;
			resets = <&cpg 728>;
			linux,uio-name = "caiplite_07";
		};

		wcrc_caiplite0 {
			compatible = "generic-uio";
			reg = <0 0xe7080000 0 0x1000>;
			clocks = <&cpg CPG_MOD 903>;
			power-domains = <&sysc R8A779F0_PD_ALWAYS_ON>;
			resets = <&cpg 903>;
			linux,uio-name = "wcrc_caiplite_00";
		};

		wcrc_caiplite1 {
			compatible = "generic-uio";
			reg = <0 0xe7090000 0 0x1000>;
			clocks = <&cpg CPG_MOD 904>;
			power-domains = <&sysc R8A779F0_PD_ALWAYS_ON>;
			resets = <&cpg 904>;
			linux,uio-name = "wcrc_caiplite_01";
		};

		wcrc_caiplite2 {
			compatible = "generic-uio";
			reg = <0 0xe70a0000 0 0x1000>;
			clocks = <&cpg CPG_MOD 905>;
			power-domains = <&sysc R8A779F0_PD_ALWAYS_ON>;
			resets = <&cpg 905>;
			linux,uio-name = "wcrc_caiplite_02";
		};

		wcrc_caiplite3 {
			compatible = "generic-uio";
			reg = <0 0xe70b0000 0 0x1000>;
			clocks = <&cpg CPG_MOD 906>;
			power-domains = <&sysc R8A779F0_PD_ALWAYS_ON>;
			resets = <&cpg 906>;
			linux,uio-name = "wcrc_caiplite_03";
		};

		rtdmac_control0: rtdmac_control@ffc10000 {
			compatible = "generic-uio";
			reg = <0 0xffc10000 0 0x10000>;
			interrupts = <GIC_SPI 30 IRQ_TYPE_LEVEL_HIGH>;
			clocks = <&cpg CPG_MOD 630>;
			power-domains = <&sysc R8A779F0_PD_ALWAYS_ON>;
			resets = <&cpg 630>;
			linux,uio-name = "rtdmac_control_00";
			ipmmu-id = <RCAR_IPMMU_RT1 0>;
			iommus = <&ipmmu_rt1 0>;
			status = "disabled";
		};

		rtdmac_control001 {
			compatible = "generic-uio";
			reg = <0 0xffc10000 0 0x10000>;
			interrupts = <GIC_SPI 31 IRQ_TYPE_LEVEL_HIGH>;
			clocks = <&cpg CPG_MOD 630>;
			power-domains = <&sysc R8A779F0_PD_ALWAYS_ON>;
			linux,uio-name = "irq_rtdmac_control_00_01";
			ipmmu-id = <RCAR_IPMMU_RT1 1>;
			iommus = <&ipmmu_rt1 1>;
			status = "disabled";
		};

		rtdmac_control002 {
			compatible = "generic-uio";
			reg = <0 0xffc10000 0 0x10000>;
			interrupts = <GIC_SPI 32 IRQ_TYPE_LEVEL_HIGH>;
			clocks = <&cpg CPG_MOD 630>;
			power-domains = <&sysc R8A779F0_PD_ALWAYS_ON>;
			linux,uio-name = "irq_rtdmac_control_00_02";
			ipmmu-id = <RCAR_IPMMU_RT1 2>;
			iommus = <&ipmmu_rt1 2>;
			status = "disabled";
		};

		rtdmac_control003 {
			compatible = "generic-uio";
			reg = <0 0xffc10000 0 0x10000>;
			interrupts = <GIC_SPI 33 IRQ_TYPE_LEVEL_HIGH>;
			clocks = <&cpg CPG_MOD 630>;
			power-domains = <&sysc R8A779F0_PD_ALWAYS_ON>;
			linux,uio-name = "irq_rtdmac_control_00_03";
			ipmmu-id = <RCAR_IPMMU_RT1 3>;
			iommus = <&ipmmu_rt1 3>;
			status = "disabled";
		};

		rtdmac_control004 {
			compatible = "generic-uio";
			reg = <0 0xffc10000 0 0x10000>;
			interrupts = <GIC_SPI 34 IRQ_TYPE_LEVEL_HIGH>;
			clocks = <&cpg CPG_MOD 630>;
			power-domains = <&sysc R8A779F0_PD_ALWAYS_ON>;
			linux,uio-name = "irq_rtdmac_control_00_04";
			ipmmu-id = <RCAR_IPMMU_RT1 4>;
			iommus = <&ipmmu_rt1 4>;
			status = "disabled";
		};

		rtdmac_control005 {
			compatible = "generic-uio";
			reg = <0 0xffc10000 0 0x10000>;
			interrupts = <GIC_SPI 35 IRQ_TYPE_LEVEL_HIGH>;
			clocks = <&cpg CPG_MOD 630>;
			power-domains = <&sysc R8A779F0_PD_ALWAYS_ON>;
			ipmmu-id = <RCAR_IPMMU_RT1 5>;
			linux,uio-name = "irq_rtdmac_control_00_05";
			iommus = <&ipmmu_rt1 5>;
			status = "disabled";
		};

		rtdmac_control006 {
			compatible = "generic-uio";
			reg = <0 0xffc10000 0 0x10000>;
			interrupts = <GIC_SPI 36 IRQ_TYPE_LEVEL_HIGH>;
			clocks = <&cpg CPG_MOD 630>;
			power-domains = <&sysc R8A779F0_PD_ALWAYS_ON>;
			linux,uio-name = "irq_rtdmac_control_00_06";
			ipmmu-id = <RCAR_IPMMU_RT1 6>;
			iommus = <&ipmmu_rt1 6>;
			status = "disabled";
		};

		rtdmac_control007 {
			compatible = "generic-uio";
			reg = <0 0xffc10000 0 0x10000>;
			interrupts = <GIC_SPI 37 IRQ_TYPE_LEVEL_HIGH>;
			clocks = <&cpg CPG_MOD 630>;
			power-domains = <&sysc R8A779F0_PD_ALWAYS_ON>;
			linux,uio-name = "irq_rtdmac_control_00_07";
			ipmmu-id = <RCAR_IPMMU_RT1 7>;
			iommus = <&ipmmu_rt1 7>;
			status = "disabled";
		};

		rtdmac_control008 {
			compatible = "generic-uio";
			reg = <0 0xffc10000 0 0x10000>;
			interrupts = <GIC_SPI 38 IRQ_TYPE_LEVEL_HIGH>;
			clocks = <&cpg CPG_MOD 630>;
			power-domains = <&sysc R8A779F0_PD_ALWAYS_ON>;
			linux,uio-name = "irq_rtdmac_control_00_08";
			ipmmu-id = <RCAR_IPMMU_RT1 8>;
			iommus = <&ipmmu_rt1 8>;
			status = "disabled";
		};

		rtdmac_control009 {
			compatible = "generic-uio";
			reg = <0 0xffc10000 0 0x10000>;
			interrupts = <GIC_SPI 39 IRQ_TYPE_LEVEL_HIGH>;
			clocks = <&cpg CPG_MOD 630>;
			power-domains = <&sysc R8A779F0_PD_ALWAYS_ON>;
			linux,uio-name = "irq_rtdmac_control_00_09";
			ipmmu-id = <RCAR_IPMMU_RT1 9>;
			iommus = <&ipmmu_rt1 9>;
			status = "disabled";
		};

		rtdmac_control010 {
			compatible = "generic-uio";
			reg = <0 0xffc10000 0 0x10000>;
			interrupts = <GIC_SPI 40 IRQ_TYPE_LEVEL_HIGH>;
			clocks = <&cpg CPG_MOD 630>;
			power-domains = <&sysc R8A779F0_PD_ALWAYS_ON>;
			linux,uio-name = "irq_rtdmac_control_00_10";
			ipmmu-id = <RCAR_IPMMU_RT1 10>;
			iommus = <&ipmmu_rt1 10>;
			status = "disabled";
		};

		rtdmac_control011 {
			compatible = "generic-uio";
			reg = <0 0xffc10000 0 0x10000>;
			interrupts = <GIC_SPI 41 IRQ_TYPE_LEVEL_HIGH>;
			clocks = <&cpg CPG_MOD 630>;
			power-domains = <&sysc R8A779F0_PD_ALWAYS_ON>;
			linux,uio-name = "irq_rtdmac_control_00_11";
			ipmmu-id = <RCAR_IPMMU_RT1 11>;
			iommus = <&ipmmu_rt1 11>;
			status = "disabled";
		};

		rtdmac_control012 {
			compatible = "generic-uio";
			reg = <0 0xffc10000 0 0x10000>;
			interrupts = <GIC_SPI 42 IRQ_TYPE_LEVEL_HIGH>;
			clocks = <&cpg CPG_MOD 630>;
			power-domains = <&sysc R8A779F0_PD_ALWAYS_ON>;
			linux,uio-name = "irq_rtdmac_control_00_12";
			ipmmu-id = <RCAR_IPMMU_RT1 12>;
			iommus = <&ipmmu_rt1 12>;
			status = "disabled";
		};

		rtdmac_control013 {
			compatible = "generic-uio";
			reg = <0 0xffc10000 0 0x10000>;
			interrupts = <GIC_SPI 43 IRQ_TYPE_LEVEL_HIGH>;
			clocks = <&cpg CPG_MOD 630>;
			power-domains = <&sysc R8A779F0_PD_ALWAYS_ON>;
			ipmmu-id = <RCAR_IPMMU_RT1 13>;
			linux,uio-name = "irq_rtdmac_control_00_13";
			iommus = <&ipmmu_rt1 13>;
			status = "disabled";
		};

		rtdmac_control014 {
			compatible = "generic-uio";
			reg = <0 0xffc10000 0 0x10000>;
			interrupts = <GIC_SPI 44 IRQ_TYPE_LEVEL_HIGH>;
			clocks = <&cpg CPG_MOD 630>;
			power-domains = <&sysc R8A779F0_PD_ALWAYS_ON>;
			ipmmu-id = <RCAR_IPMMU_RT1 14>;
			linux,uio-name = "irq_rtdmac_control_00_14";
			iommus = <&ipmmu_rt1 14>;
			status = "disabled";
		};

		rtdmac_control015 {
			compatible = "generic-uio";
			reg = <0 0xffc10000 0 0x10000>;
			interrupts = <GIC_SPI 45 IRQ_TYPE_LEVEL_HIGH>;
			clocks = <&cpg CPG_MOD 630>;
			power-domains = <&sysc R8A779F0_PD_ALWAYS_ON>;
			linux,uio-name = "irq_rtdmac_control_00_15";
			ipmmu-id = <RCAR_IPMMU_RT1 15>;
			iommus = <&ipmmu_rt1 15>;
			status = "disabled";
		};

		rtdmac_control1: rtdmac_control@ffc20000 {
			compatible = "generic-uio";
			reg = <0 0xffc20000 0 0x10000>;
			interrupts = <GIC_SPI 48 IRQ_TYPE_LEVEL_HIGH>;
			clocks = <&cpg CPG_MOD 631>;
			power-domains = <&sysc R8A779F0_PD_ALWAYS_ON>;
			resets = <&cpg 631>;
			linux,uio-name = "rtdmac_control_01";
			ipmmu-id = <RCAR_IPMMU_RT1 16>;
			iommus = <&ipmmu_rt1 16>;
			status = "disabled";
		};

		rtdmac_control101 {
			compatible = "generic-uio";
			reg = <0 0xffc20000 0 0x10000>;
			interrupts = <GIC_SPI 49 IRQ_TYPE_LEVEL_HIGH>;
			clocks = <&cpg CPG_MOD 631>;
			power-domains = <&sysc R8A779F0_PD_ALWAYS_ON>;
			linux,uio-name = "irq_rtdmac_control_01_01";
			ipmmu-id = <RCAR_IPMMU_RT1 17>;
			iommus = <&ipmmu_rt1 17>;
			status = "disabled";
		};

		rtdmac_control102 {
			compatible = "generic-uio";
			reg = <0 0xffc20000 0 0x10000>;
			interrupts = <GIC_SPI 50 IRQ_TYPE_LEVEL_HIGH>;
			clocks = <&cpg CPG_MOD 631>;
			power-domains = <&sysc R8A779F0_PD_ALWAYS_ON>;
			linux,uio-name = "irq_rtdmac_control_01_02";
			ipmmu-id = <RCAR_IPMMU_RT1 18>;
			iommus = <&ipmmu_rt1 18>;
			status = "disabled";
		};

		rtdmac_control103 {
			compatible = "generic-uio";
			reg = <0 0xffc20000 0 0x10000>;
			interrupts = <GIC_SPI 51 IRQ_TYPE_LEVEL_HIGH>;
			clocks = <&cpg CPG_MOD 631>;
			power-domains = <&sysc R8A779F0_PD_ALWAYS_ON>;
			linux,uio-name = "irq_rtdmac_control_01_03";
			ipmmu-id = <RCAR_IPMMU_RT1 19>;
			iommus = <&ipmmu_rt1 19>;
			status = "disabled";
		};

		rtdmac_control104 {
			compatible = "generic-uio";
			reg = <0 0xffc20000 0 0x10000>;
			interrupts = <GIC_SPI 52 IRQ_TYPE_LEVEL_HIGH>;
			clocks = <&cpg CPG_MOD 631>;
			power-domains = <&sysc R8A779F0_PD_ALWAYS_ON>;
			linux,uio-name = "irq_rtdmac_control_01_04";
			ipmmu-id = <RCAR_IPMMU_RT1 20>;
			iommus = <&ipmmu_rt1 20>;
			status = "disabled";
		};

		rtdmac_control105 {
			compatible = "generic-uio";
			reg = <0 0xffc20000 0 0x10000>;
			interrupts = <GIC_SPI 53 IRQ_TYPE_LEVEL_HIGH>;
			clocks = <&cpg CPG_MOD 631>;
			power-domains = <&sysc R8A779F0_PD_ALWAYS_ON>;
			linux,uio-name = "irq_rtdmac_control_01_05";
			ipmmu-id = <RCAR_IPMMU_RT1 21>;
			iommus = <&ipmmu_rt1 21>;
			status = "disabled";
		};

		rtdmac_control106 {
			compatible = "generic-uio";
			reg = <0 0xffc20000 0 0x10000>;
			interrupts = <GIC_SPI 54 IRQ_TYPE_LEVEL_HIGH>;
			clocks = <&cpg CPG_MOD 631>;
			power-domains = <&sysc R8A779F0_PD_ALWAYS_ON>;
			linux,uio-name = "irq_rtdmac_control_01_06";
			ipmmu-id = <RCAR_IPMMU_RT1 22>;
			iommus = <&ipmmu_rt1 22>;
			status = "disabled";
		};

		rtdmac_control107 {
			compatible = "generic-uio";
			reg = <0 0xffc20000 0 0x10000>;
			interrupts = <GIC_SPI 55 IRQ_TYPE_LEVEL_HIGH>;
			clocks = <&cpg CPG_MOD 631>;
			power-domains = <&sysc R8A779F0_PD_ALWAYS_ON>;
			linux,uio-name = "irq_rtdmac_control_01_07";
			ipmmu-id = <RCAR_IPMMU_RT1 23>;
			iommus = <&ipmmu_rt1 23>;
			status = "disabled";
		};

		rtdmac_control108 {
			compatible = "generic-uio";
			reg = <0 0xffc20000 0 0x10000>;
			interrupts = <GIC_SPI 56 IRQ_TYPE_LEVEL_HIGH>;
			clocks = <&cpg CPG_MOD 631>;
			power-domains = <&sysc R8A779F0_PD_ALWAYS_ON>;
			linux,uio-name = "irq_rtdmac_control_01_08";
			ipmmu-id = <RCAR_IPMMU_RT1 24>;
			iommus = <&ipmmu_rt1 24>;
			status = "disabled";
		};

		rtdmac_control109 {
			compatible = "generic-uio";
			reg = <0 0xffc20000 0 0x10000>;
			interrupts = <GIC_SPI 57 IRQ_TYPE_LEVEL_HIGH>;
			clocks = <&cpg CPG_MOD 631>;
			power-domains = <&sysc R8A779F0_PD_ALWAYS_ON>;
			linux,uio-name = "irq_rtdmac_control_01_09";
			ipmmu-id = <RCAR_IPMMU_RT1 25>;
			iommus = <&ipmmu_rt1 25>;
			status = "disabled";
		};

		rtdmac_control110 {
			compatible = "generic-uio";
			reg = <0 0xffc20000 0 0x10000>;
			interrupts = <GIC_SPI 58 IRQ_TYPE_LEVEL_HIGH>;
			clocks = <&cpg CPG_MOD 631>;
			power-domains = <&sysc R8A779F0_PD_ALWAYS_ON>;
			linux,uio-name = "irq_rtdmac_control_01_10";
			ipmmu-id = <RCAR_IPMMU_RT1 26>;
			iommus = <&ipmmu_rt1 26>;
			status = "disabled";
		};

		rtdmac_control111 {
			compatible = "generic-uio";
			reg = <0 0xffc20000 0 0x10000>;
			interrupts = <GIC_SPI 59 IRQ_TYPE_LEVEL_HIGH>;
			clocks = <&cpg CPG_MOD 631>;
			power-domains = <&sysc R8A779F0_PD_ALWAYS_ON>;
			linux,uio-name = "irq_rtdmac_control_01_11";
			ipmmu-id = <RCAR_IPMMU_RT1 27>;
			iommus = <&ipmmu_rt1 27>;
			status = "disabled";
		};

		rtdmac_control112 {
			compatible = "generic-uio";
			reg = <0 0xffc20000 0 0x10000>;
			interrupts = <GIC_SPI 60 IRQ_TYPE_LEVEL_HIGH>;
			clocks = <&cpg CPG_MOD 631>;
			power-domains = <&sysc R8A779F0_PD_ALWAYS_ON>;
			linux,uio-name = "irq_rtdmac_control_01_12";
			ipmmu-id = <RCAR_IPMMU_RT1 28>;
			iommus = <&ipmmu_rt1 28>;
			status = "disabled";
		};

		rtdmac_control113 {
			compatible = "generic-uio";
			reg = <0 0xffc20000 0 0x10000>;
			interrupts = <GIC_SPI 61 IRQ_TYPE_LEVEL_HIGH>;
			clocks = <&cpg CPG_MOD 631>;
			power-domains = <&sysc R8A779F0_PD_ALWAYS_ON>;
			linux,uio-name = "irq_rtdmac_control_01_13";
			ipmmu-id = <RCAR_IPMMU_RT1 29>;
			iommus = <&ipmmu_rt1 29>;
			status = "disabled";
		};

		rtdmac_control114 {
			compatible = "generic-uio";
			reg = <0 0xffc20000 0 0x10000>;
			interrupts = <GIC_SPI 62 IRQ_TYPE_LEVEL_HIGH>;
			clocks = <&cpg CPG_MOD 631>;
			power-domains = <&sysc R8A779F0_PD_ALWAYS_ON>;
			linux,uio-name = "irq_rtdmac_control_01_14";
			ipmmu-id = <RCAR_IPMMU_RT1 30>;
			iommus = <&ipmmu_rt1 30>;
			status = "disabled";
		};

		rtdmac_control115 {
			compatible = "generic-uio";
			reg = <0 0xffc20000 0 0x10000>;
			interrupts = <GIC_SPI 63 IRQ_TYPE_LEVEL_HIGH>;
			clocks = <&cpg CPG_MOD 631>;
			power-domains = <&sysc R8A779F0_PD_ALWAYS_ON>;
			linux,uio-name = "irq_rtdmac_control_01_15";
			ipmmu-id = <RCAR_IPMMU_RT1 31>;
			iommus = <&ipmmu_rt1 31>;
			status = "disabled";
		};

		rtdmac_control2: rtdmac_control@ffd70000 {
			compatible = "generic-uio";
			reg = <0 0xffd70000 0 0x10000>;
			interrupts = <GIC_SPI 66 IRQ_TYPE_LEVEL_HIGH>;
			clocks = <&cpg CPG_MOD 700>;
			power-domains = <&sysc R8A779F0_PD_ALWAYS_ON>;
			resets = <&cpg 700>;
			linux,uio-name = "rtdmac_control_02";
			ipmmu-id = <RCAR_IPMMU_RT1 32>;
			iommus = <&ipmmu_rt1 32>;
			status = "disabled";
		};

		rtdmac_control201 {
			compatible = "generic-uio";
			reg = <0 0xffd70000 0 0x10000>;
			interrupts = <GIC_SPI 67 IRQ_TYPE_LEVEL_HIGH>;
			clocks = <&cpg CPG_MOD 700>;
			power-domains = <&sysc R8A779F0_PD_ALWAYS_ON>;
			linux,uio-name = "irq_rtdmac_control_02_01";
			ipmmu-id = <RCAR_IPMMU_RT1 33>;
			iommus = <&ipmmu_rt1 33>;
			status = "disabled";
		};

		rtdmac_control202 {
			compatible = "generic-uio";
			reg = <0 0xffd70000 0 0x10000>;
			interrupts = <GIC_SPI 68 IRQ_TYPE_LEVEL_HIGH>;
			clocks = <&cpg CPG_MOD 700>;
			power-domains = <&sysc R8A779F0_PD_ALWAYS_ON>;
			linux,uio-name = "irq_rtdmac_control_02_02";
			ipmmu-id = <RCAR_IPMMU_RT1 34>;
			iommus = <&ipmmu_rt1 34>;
			status = "disabled";
		};

		rtdmac_control203 {
			compatible = "generic-uio";
			reg = <0 0xffd70000 0 0x10000>;
			interrupts = <GIC_SPI 69 IRQ_TYPE_LEVEL_HIGH>;
			clocks = <&cpg CPG_MOD 700>;
			power-domains = <&sysc R8A779F0_PD_ALWAYS_ON>;
			linux,uio-name = "irq_rtdmac_control_02_03";
			ipmmu-id = <RCAR_IPMMU_RT1 35>;
			iommus = <&ipmmu_rt1 35>;
			status = "disabled";
		};

		rtdmac_control204 {
			compatible = "generic-uio";
			reg = <0 0xffd70000 0 0x10000>;
			interrupts = <GIC_SPI 70 IRQ_TYPE_LEVEL_HIGH>;
			clocks = <&cpg CPG_MOD 700>;
			power-domains = <&sysc R8A779F0_PD_ALWAYS_ON>;
			linux,uio-name = "irq_rtdmac_control_02_04";
			ipmmu-id = <RCAR_IPMMU_RT1 36>;
			iommus = <&ipmmu_rt1 36>;
			status = "disabled";
		};

		rtdmac_control205 {
			compatible = "generic-uio";
			reg = <0 0xffd70000 0 0x10000>;
			interrupts = <GIC_SPI 71 IRQ_TYPE_LEVEL_HIGH>;
			clocks = <&cpg CPG_MOD 700>;
			power-domains = <&sysc R8A779F0_PD_ALWAYS_ON>;
			linux,uio-name = "irq_rtdmac_control_02_05";
			ipmmu-id = <RCAR_IPMMU_RT1 37>;
			iommus = <&ipmmu_rt1 37>;
			status = "disabled";
		};

		rtdmac_control206 {
			compatible = "generic-uio";
			reg = <0 0xffd70000 0 0x10000>;
			interrupts = <GIC_SPI 72 IRQ_TYPE_LEVEL_HIGH>;
			clocks = <&cpg CPG_MOD 700>;
			power-domains = <&sysc R8A779F0_PD_ALWAYS_ON>;
			linux,uio-name = "irq_rtdmac_control_02_06";
			ipmmu-id = <RCAR_IPMMU_RT1 38>;
			iommus = <&ipmmu_rt1 38>;
			status = "disabled";
		};

		rtdmac_control207 {
			compatible = "generic-uio";
			reg = <0 0xffd70000 0 0x10000>;
			interrupts = <GIC_SPI 73 IRQ_TYPE_LEVEL_HIGH>;
			clocks = <&cpg CPG_MOD 700>;
			power-domains = <&sysc R8A779F0_PD_ALWAYS_ON>;
			linux,uio-name = "irq_rtdmac_control_02_07";
			ipmmu-id = <RCAR_IPMMU_RT1 39>;
			iommus = <&ipmmu_rt1 39>;
			status = "disabled";
		};

		rtdmac_control208 {
			compatible = "generic-uio";
			reg = <0 0xffd70000 0 0x10000>;
			interrupts = <GIC_SPI 74 IRQ_TYPE_LEVEL_HIGH>;
			clocks = <&cpg CPG_MOD 700>;
			power-domains = <&sysc R8A779F0_PD_ALWAYS_ON>;
			linux,uio-name = "irq_rtdmac_control_02_08";
			ipmmu-id = <RCAR_IPMMU_RT1 40>;
			iommus = <&ipmmu_rt1 40>;
			status = "disabled";
		};

		rtdmac_control209 {
			compatible = "generic-uio";
			reg = <0 0xffd70000 0 0x10000>;
			interrupts = <GIC_SPI 75 IRQ_TYPE_LEVEL_HIGH>;
			clocks = <&cpg CPG_MOD 700>;
			power-domains = <&sysc R8A779F0_PD_ALWAYS_ON>;
			linux,uio-name = "irq_rtdmac_control_02_09";
			ipmmu-id = <RCAR_IPMMU_RT1 41>;
			iommus = <&ipmmu_rt1 41>;
			status = "disabled";
		};

		rtdmac_control210 {
			compatible = "generic-uio";
			reg = <0 0xffd70000 0 0x10000>;
			interrupts = <GIC_SPI 76 IRQ_TYPE_LEVEL_HIGH>;
			clocks = <&cpg CPG_MOD 700>;
			power-domains = <&sysc R8A779F0_PD_ALWAYS_ON>;
			linux,uio-name = "irq_rtdmac_control_02_10";
			ipmmu-id = <RCAR_IPMMU_RT1 42>;
			iommus = <&ipmmu_rt1 42>;
			status = "disabled";
		};

		rtdmac_control211 {
			compatible = "generic-uio";
			reg = <0 0xffd70000 0 0x10000>;
			interrupts = <GIC_SPI 77 IRQ_TYPE_LEVEL_HIGH>;
			clocks = <&cpg CPG_MOD 700>;
			power-domains = <&sysc R8A779F0_PD_ALWAYS_ON>;
			linux,uio-name = "irq_rtdmac_control_02_11";
			ipmmu-id = <RCAR_IPMMU_RT1 43>;
			iommus = <&ipmmu_rt1 43>;
			status = "disabled";
		};

		rtdmac_control212 {
			compatible = "generic-uio";
			reg = <0 0xffd70000 0 0x10000>;
			interrupts = <GIC_SPI 78 IRQ_TYPE_LEVEL_HIGH>;
			clocks = <&cpg CPG_MOD 700>;
			power-domains = <&sysc R8A779F0_PD_ALWAYS_ON>;
			linux,uio-name = "irq_rtdmac_control_02_12";
			ipmmu-id = <RCAR_IPMMU_RT1 44>;
			iommus = <&ipmmu_rt1 44>;
			status = "disabled";
		};

		rtdmac_control213 {
			compatible = "generic-uio";
			reg = <0 0xffd70000 0 0x10000>;
			interrupts = <GIC_SPI 79 IRQ_TYPE_LEVEL_HIGH>;
			clocks = <&cpg CPG_MOD 700>;
			power-domains = <&sysc R8A779F0_PD_ALWAYS_ON>;
			linux,uio-name = "irq_rtdmac_control_02_13";
			ipmmu-id = <RCAR_IPMMU_RT1 45>;
			iommus = <&ipmmu_rt1 45>;
			status = "disabled";
		};

		rtdmac_control214 {
			compatible = "generic-uio";
			reg = <0 0xffd70000 0 0x10000>;
			interrupts = <GIC_SPI 80 IRQ_TYPE_LEVEL_HIGH>;
			clocks = <&cpg CPG_MOD 700>;
			power-domains = <&sysc R8A779F0_PD_ALWAYS_ON>;
			linux,uio-name = "irq_rtdmac_control_02_14";
			ipmmu-id = <RCAR_IPMMU_RT1 46>;
			iommus = <&ipmmu_rt1 46>;
			status = "disabled";
		};

		rtdmac_control215 {
			compatible = "generic-uio";
			reg = <0 0xffd70000 0 0x10000>;
			interrupts = <GIC_SPI 81 IRQ_TYPE_LEVEL_HIGH>;
			clocks = <&cpg CPG_MOD 700>;
			power-domains = <&sysc R8A779F0_PD_ALWAYS_ON>;
			linux,uio-name = "irq_rtdmac_control_02_15";
			ipmmu-id = <RCAR_IPMMU_RT1 47>;
			iommus = <&ipmmu_rt1 47>;
			status = "disabled";
		};

		rtdmac_control3: rtdmac_control@ffd80000 {
			compatible = "generic-uio";
			reg = <0 0xffd80000 0 0x10000>;
			interrupts = <GIC_SPI 84 IRQ_TYPE_LEVEL_HIGH>;
			clocks = <&cpg CPG_MOD 701>;
			power-domains = <&sysc R8A779F0_PD_ALWAYS_ON>;
			resets = <&cpg 701>;
			linux,uio-name = "rtdmac_control_03";
			ipmmu-id = <RCAR_IPMMU_RT1 48>;
			iommus = <&ipmmu_rt1 48>;
			status = "disabled";
		};

		rtdmac_control301 {
			compatible = "generic-uio";
			reg = <0 0xffd80000 0 0x10000>;
			interrupts = <GIC_SPI 85 IRQ_TYPE_LEVEL_HIGH>;
			clocks = <&cpg CPG_MOD 701>;
			power-domains = <&sysc R8A779F0_PD_ALWAYS_ON>;
			linux,uio-name = "irq_rtdmac_control_03_01";
			ipmmu-id = <RCAR_IPMMU_RT1 49>;
			iommus = <&ipmmu_rt1 49>;
		};

		rtdmac_control302 {
			compatible = "generic-uio";
			reg = <0 0xffd80000 0 0x10000>;
			interrupts = <GIC_SPI 86 IRQ_TYPE_LEVEL_HIGH>;
			clocks = <&cpg CPG_MOD 701>;
			power-domains = <&sysc R8A779F0_PD_ALWAYS_ON>;
			linux,uio-name = "irq_rtdmac_control_03_02";
			ipmmu-id = <RCAR_IPMMU_RT1 50>;
			iommus = <&ipmmu_rt1 50>;
			status = "disabled";
		};

		rtdmac_control303 {
			compatible = "generic-uio";
			reg = <0 0xffd80000 0 0x10000>;
			interrupts = <GIC_SPI 87 IRQ_TYPE_LEVEL_HIGH>;
			clocks = <&cpg CPG_MOD 701>;
			power-domains = <&sysc R8A779F0_PD_ALWAYS_ON>;
			linux,uio-name = "irq_rtdmac_control_03_03";
			ipmmu-id = <RCAR_IPMMU_RT1 51>;
			iommus = <&ipmmu_rt1 51>;
			status = "disabled";
		};

		rtdmac_control304 {
			compatible = "generic-uio";
			reg = <0 0xffd80000 0 0x10000>;
			interrupts = <GIC_SPI 88 IRQ_TYPE_LEVEL_HIGH>;
			clocks = <&cpg CPG_MOD 701>;
			power-domains = <&sysc R8A779F0_PD_ALWAYS_ON>;
			linux,uio-name = "irq_rtdmac_control_03_04";
			ipmmu-id = <RCAR_IPMMU_RT1 52>;
			iommus = <&ipmmu_rt1 52>;
			status = "disabled";
		};

		rtdmac_control305 {
			compatible = "generic-uio";
			reg = <0 0xffd80000 0 0x10000>;
			interrupts = <GIC_SPI 89 IRQ_TYPE_LEVEL_HIGH>;
			clocks = <&cpg CPG_MOD 701>;
			power-domains = <&sysc R8A779F0_PD_ALWAYS_ON>;
			linux,uio-name = "irq_rtdmac_control_03_05";
			ipmmu-id = <RCAR_IPMMU_RT1 53>;
			iommus = <&ipmmu_rt1 53>;
			status = "disabled";
		};

		rtdmac_control306 {
			compatible = "generic-uio";
			reg = <0 0xffd80000 0 0x10000>;
			interrupts = <GIC_SPI 90 IRQ_TYPE_LEVEL_HIGH>;
			clocks = <&cpg CPG_MOD 701>;
			power-domains = <&sysc R8A779F0_PD_ALWAYS_ON>;
			linux,uio-name = "irq_rtdmac_control_03_06";
			ipmmu-id = <RCAR_IPMMU_RT1 54>;
			iommus = <&ipmmu_rt1 54>;
			status = "disabled";
		};

		rtdmac_control307 {
			compatible = "generic-uio";
			reg = <0 0xffd80000 0 0x10000>;
			interrupts = <GIC_SPI 91 IRQ_TYPE_LEVEL_HIGH>;
			clocks = <&cpg CPG_MOD 701>;
			power-domains = <&sysc R8A779F0_PD_ALWAYS_ON>;
			linux,uio-name = "irq_rtdmac_control_03_07";
			ipmmu-id = <RCAR_IPMMU_RT1 55>;
			iommus = <&ipmmu_rt1 55>;
			status = "disabled";
		};

		rtdmac_control308 {
			compatible = "generic-uio";
			reg = <0 0xffd80000 0 0x10000>;
			interrupts = <GIC_SPI 92 IRQ_TYPE_LEVEL_HIGH>;
			clocks = <&cpg CPG_MOD 701>;
			power-domains = <&sysc R8A779F0_PD_ALWAYS_ON>;
			linux,uio-name = "irq_rtdmac_control_03_08";
			ipmmu-id = <RCAR_IPMMU_RT1 56>;
			iommus = <&ipmmu_rt1 56>;
			status = "disabled";
		};

		rtdmac_control309 {
			compatible = "generic-uio";
			reg = <0 0xffd80000 0 0x10000>;
			interrupts = <GIC_SPI 93 IRQ_TYPE_LEVEL_HIGH>;
			clocks = <&cpg CPG_MOD 701>;
			power-domains = <&sysc R8A779F0_PD_ALWAYS_ON>;
			linux,uio-name = "irq_rtdmac_control_03_09";
			ipmmu-id = <RCAR_IPMMU_RT1 57>;
			iommus = <&ipmmu_rt1 57>;
			status = "disabled";
		};

		rtdmac_control310 {
			compatible = "generic-uio";
			reg = <0 0xffd80000 0 0x10000>;
			interrupts = <GIC_SPI 94 IRQ_TYPE_LEVEL_HIGH>;
			clocks = <&cpg CPG_MOD 701>;
			power-domains = <&sysc R8A779F0_PD_ALWAYS_ON>;
			linux,uio-name = "irq_rtdmac_control_03_10";
			ipmmu-id = <RCAR_IPMMU_RT1 58>;
			iommus = <&ipmmu_rt1 58>;
			status = "disabled";
		};

		rtdmac_control311 {
			compatible = "generic-uio";
			reg = <0 0xffd80000 0 0x10000>;
			interrupts = <GIC_SPI 95 IRQ_TYPE_LEVEL_HIGH>;
			clocks = <&cpg CPG_MOD 701>;
			power-domains = <&sysc R8A779F0_PD_ALWAYS_ON>;
			linux,uio-name = "irq_rtdmac_control_03_11";
			ipmmu-id = <RCAR_IPMMU_RT1 59>;
			iommus = <&ipmmu_rt1 59>;
			status = "disabled";
		};

		rtdmac_control312 {
			compatible = "generic-uio";
			reg = <0 0xffd80000 0 0x10000>;
			interrupts = <GIC_SPI 96 IRQ_TYPE_LEVEL_HIGH>;
			clocks = <&cpg CPG_MOD 701>;
			power-domains = <&sysc R8A779F0_PD_ALWAYS_ON>;
			linux,uio-name = "irq_rtdmac_control_03_12";
			ipmmu-id = <RCAR_IPMMU_RT1 60>;
			iommus = <&ipmmu_rt1 60>;
			status = "disabled";
		};

		rtdmac_control313 {
			compatible = "generic-uio";
			reg = <0 0xffd80000 0 0x10000>;
			interrupts = <GIC_SPI 97 IRQ_TYPE_LEVEL_HIGH>;
			clocks = <&cpg CPG_MOD 701>;
			power-domains = <&sysc R8A779F0_PD_ALWAYS_ON>;
			linux,uio-name = "irq_rtdmac_control_03_13";
			ipmmu-id = <RCAR_IPMMU_RT1 61>;
			iommus = <&ipmmu_rt1 61>;
			status = "disabled";
		};

		rtdmac_control314 {
			compatible = "generic-uio";
			reg = <0 0xffd80000 0 0x10000>;
			interrupts = <GIC_SPI 98 IRQ_TYPE_LEVEL_HIGH>;
			clocks = <&cpg CPG_MOD 701>;
			power-domains = <&sysc R8A779F0_PD_ALWAYS_ON>;
			linux,uio-name = "irq_rtdmac_control_03_14";
			ipmmu-id = <RCAR_IPMMU_RT1 62>;
			iommus = <&ipmmu_rt1 62>;
			status = "disabled";
		};

		rtdmac_control315 {
			compatible = "generic-uio";
			reg = <0 0xffd80000 0 0x10000>;
			interrupts = <GIC_SPI 99 IRQ_TYPE_LEVEL_HIGH>;
			clocks = <&cpg CPG_MOD 701>;
			power-domains = <&sysc R8A779F0_PD_ALWAYS_ON>;
			linux,uio-name = "irq_rtdmac_control_03_15";
			ipmmu-id = <RCAR_IPMMU_RT1 63>;
			iommus = <&ipmmu_rt1 63>;
			status = "disabled";
		};

		rtdmac_descriptor0: rtdmac_descriptor@ffd60000 {
			compatible = "generic-uio";
			reg = <0 0xffd60000 0 0x1000>;
			clocks = <&cpg CPG_MOD 630>;
			power-domains = <&sysc R8A779F0_PD_ALWAYS_ON>;
			linux,uio-name = "rtdmac_descriptor_00";
		};

		rtdmac_descriptor1: rtdmac_descriptor@ffd61000 {
			compatible = "generic-uio";
			reg = <0 0xffd61000 0 0x1000>;
			clocks = <&cpg CPG_MOD 631>;
			power-domains = <&sysc R8A779F0_PD_ALWAYS_ON>;
			linux,uio-name = "rtdmac_descriptor_01";
		};

		rtdmac_descriptor2: rtdmac_descriptor@ffd62000 {
			compatible = "generic-uio";
			reg = <0 0xffd62000 0 0x1000>;
			clocks = <&cpg CPG_MOD 700>;
			power-domains = <&sysc R8A779F0_PD_ALWAYS_ON>;
			linux,uio-name = "rtdmac_descriptor_02";
		};

		rtdmac_descriptor3: rtdmac_descriptor@ffd63000 {
			compatible = "generic-uio";
			reg = <0 0xffd63000 0 0x1000>;
			clocks = <&cpg CPG_MOD 701>;
			power-domains = <&sysc R8A779F0_PD_ALWAYS_ON>;
			linux,uio-name = "rtdmac_descriptor_03";
		};

		ships0: ships0@e7810000 {
			compatible = "generic-uio";
			reg = <0 0xe7810000 0 0x10000>;
			interrupts = <GIC_SPI 948 IRQ_TYPE_LEVEL_HIGH>;
			clocks = <&cpg CPG_MOD 719>;
			power-domains = <&sysc R8A779F0_PD_ALWAYS_ON>;
			resets = <&cpg 719>;
			linux,uio-name = "ships_00";
		};

		ships0_01 {
			compatible = "generic-uio";
			reg = <0 0xe7810000 0 0x10000>;
			interrupts = <GIC_SPI 949 IRQ_TYPE_LEVEL_HIGH>;
			clocks = <&cpg CPG_MOD 719>;
			power-domains = <&sysc R8A779F0_PD_ALWAYS_ON>;
			linux,uio-name = "irq_ships_00_01";
		};

		ships1: ships1@e7820000 {
			compatible = "generic-uio";
			reg = <0 0xe7820000 0 0x10000>;
			interrupts = <GIC_SPI 950 IRQ_TYPE_LEVEL_HIGH>;
			clocks = <&cpg CPG_MOD 1511>;
			power-domains = <&sysc R8A779F0_PD_ALWAYS_ON>;
			resets = <&cpg 1511>;
			linux,uio-name = "ships_01";
		};

		ships1_01 {
			compatible = "generic-uio";
			reg = <0 0xe7820000 0 0x10000>;
			interrupts = <GIC_SPI 951 IRQ_TYPE_LEVEL_HIGH>;
			clocks = <&cpg CPG_MOD 1511>;
			power-domains = <&sysc R8A779F0_PD_ALWAYS_ON>;
			linux,uio-name = "irq_ships_01_01";
		};

		ships2: ships2@e7830000 {
			compatible = "generic-uio";
			reg = <0 0xe7830000 0 0x10000>;
			interrupts = <GIC_SPI 952 IRQ_TYPE_LEVEL_HIGH>;
			clocks = <&cpg CPG_MOD 1512>;
			power-domains = <&sysc R8A779F0_PD_ALWAYS_ON>;
			resets = <&cpg 1512>;
			linux,uio-name = "ships_02";
		};

		ships2_01 {
			compatible = "generic-uio";
			reg = <0 0xe7830000 0 0x10000>;
			interrupts = <GIC_SPI 953 IRQ_TYPE_LEVEL_HIGH>;
			clocks = <&cpg CPG_MOD 1512>;
			power-domains = <&sysc R8A779F0_PD_ALWAYS_ON>;
			linux,uio-name = "irq_ships_02_01";
		};

		systemram0: systemram@e6300000 {
			compatible = "generic-uio";
			reg = <0 0xe6300000 0 0x60000>;
			power-domains = <&sysc R8A779F0_PD_ALWAYS_ON>;
			linux,uio-name = "system_ram_00";
		};

		ufs: scsi@e6860000 {
			compatible = "renesas,r8a779f0-ufs";
			reg = <0 0xe6860000 0 0x100>;
			interrupts = <GIC_SPI 235 IRQ_TYPE_LEVEL_HIGH>;
			clocks = <&cpg CPG_MOD 1514>, <&ufs30_clk>;
			clock-names = "fck", "ref_clk";
			freq-table-hz = <200000000 200000000>, <38400000 38400000>;
			power-domains = <&sysc R8A779F0_PD_ALWAYS_ON>;
			resets = <&cpg 1514>;
			status = "disabled";
		};
	};

	thermal-zones {
		sensor_thermal1: sensor-thermal1 {
			polling-delay-passive = <250>;
			polling-delay = <1000>;
			thermal-sensors = <&tsc 0>;
			//sustainable-power = <1000>;

			trips {
				sensor1_crit: sensor1-crit {
					temperature = <120000>;
					hysteresis = <1000>;
					type = "critical";
				};
			};
		};

		sensor_thermal2: sensor-thermal2 {
			polling-delay-passive = <250>;
			polling-delay = <1000>;
			thermal-sensors = <&tsc 1>;
			//sustainable-power = <1000>;

			trips {
				sensor2_crit: sensor2-crit {
					temperature = <120000>;
					hysteresis = <1000>;
					type = "critical";
				};
			};
		};

		sensor_thermal3: sensor-thermal3 {
			polling-delay-passive = <250>;
			polling-delay = <1000>;
			thermal-sensors = <&tsc 2>;
			//sustainable-power = <1000>;

			trips {
				sensor3_crit: sensor3-crit {
					temperature = <120000>;
					hysteresis = <1000>;
					type = "critical";
				};
			};
		};
	};

	timer {
		compatible = "arm,armv8-timer";
		interrupts-extended = <&gic GIC_PPI 13 (GIC_CPU_MASK_SIMPLE(8) | IRQ_TYPE_LEVEL_LOW)>,
				      <&gic GIC_PPI 14 (GIC_CPU_MASK_SIMPLE(8) | IRQ_TYPE_LEVEL_LOW)>,
				      <&gic GIC_PPI 11 (GIC_CPU_MASK_SIMPLE(8) | IRQ_TYPE_LEVEL_LOW)>,
				      <&gic GIC_PPI 10 (GIC_CPU_MASK_SIMPLE(8) | IRQ_TYPE_LEVEL_LOW)>;
	};
};
